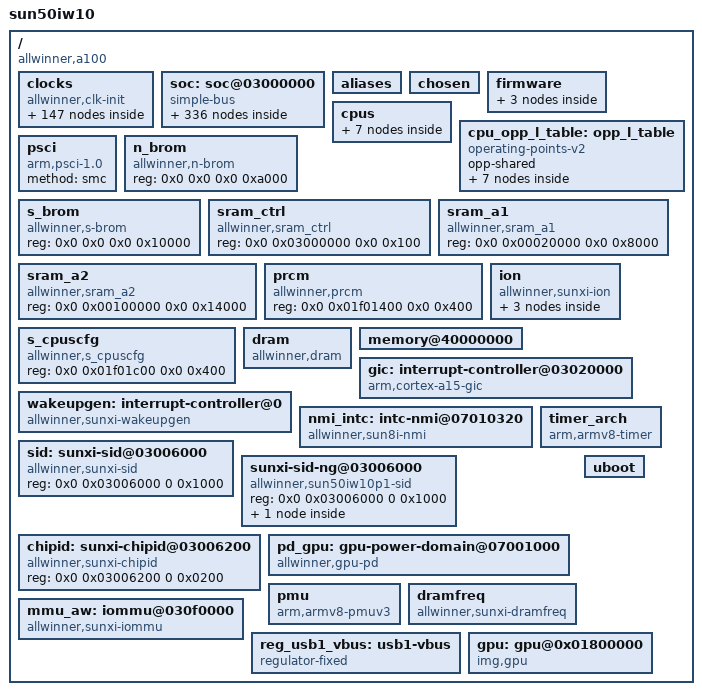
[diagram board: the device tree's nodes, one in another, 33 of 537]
/*
 * Allwinner Technology CO., Ltd. sun50iw10p1 platform
 *
 * modify base on juno.dts
 */
/dts-v1/;

/memreserve/ 0x48000000 0x01000000; /* atf */
/memreserve/ 0x48100000 0x00008000; /* arisc dram code */

#include <dt-bindings/interrupt-controller/arm-gic.h>
#include <dt-bindings/gpio/gpio.h>
/*#include "sun50iw10p1-clk.dtsi"*/
/*#include "sun50iw10p1-pinctrl.dtsi"*/
#include <dt-bindings/thermal/thermal.h>
/ {
	model = "sun50iw10";
	compatible = "allwinner,a100", "arm,sun50iw10p1";
	interrupt-parent = <&wakeupgen>;
	#address-cells = <2>;
	#size-cells = <2>;

	clocks {
		compatible = "allwinner,clk-init";
		device_type = "clocks";
		#address-cells = <2>;
		#size-cells = <2>;
		ranges;
		reg = <0x0 0x03001000 0x0 0x1000>,	/*cpux space*/
		      <0x0 0x07010000 0x0 0x400>,	/*cpus space*/
		      <0x0 0x07000000 0x0 0x4>;

	/* register fixed rate clock*/
			clk_losc: losc {
				#clock-cells = <0>;
				compatible = "allwinner,fixed-clock";
				clock-frequency = <32768>;
				clock-output-names = "losc";
			};
			clk_iosc: iosc {
				#clock-cells = <0>;
				compatible = "allwinner,fixed-clock";
				clock-frequency = <16000000>;
				clock-output-names = "iosc";
			};
			clk_hosc: hosc {
				#clock-cells = <0>;
				compatible = "allwinner,fixed-clock";
				clock-frequency = <24000000>;
				clock-output-names = "hosc";
			};
			clk_osc48m: osc48m {
				#clock-cells = <0>;
				compatible = "allwinner,fixed-clock";
				clock-frequency = <48000000>;
				clock-output-names = "osc48m";
			};
			clk_hoscdiv32k: hoscdiv32k {
				#clock-cells = <0>;
				compatible = "allwinner,fixed-clock";
				clock-frequency = <32768>;
				clock-output-names = "hoscdiv32k";
			};
			clk_pll_periph0div25m:pll_periph0div25m {
				#clock-cells = <0>;
				compatible = "allwinner,fixed-clock";
				clock-frequency = <25000000>;
				clock-output-names = "pll_periph0div25m";
			};

	/* register allwinner,pll-clock */
			clk_pll_cpu: pll_cpu {
				#clock-cells = <0>;
				compatible = "allwinner,pll-clock";
				lock-mode = "new";
				clock-output-names = "pll_cpu";
			};
			clk_pll_ddr: pll_ddr {
				#clock-cells = <0>;
				compatible = "allwinner,pll-clock";
				lock-mode = "new";
				clock-output-names = "pll_ddr";
			};
			clk_pll_periph0: pll_periph0 {
				#clock-cells = <0>;
				compatible = "allwinner,pll-clock";
				assigned-clock-rates = <600000000>;
				lock-mode = "new";
				clock-output-names = "pll_periph0";
			};
			clk_pll_periph1: pll_periph1 {
				#clock-cells = <0>;
				compatible = "allwinner,pll-clock";
				assigned-clock-rates = <600000000>;
				lock-mode = "new";
				clock-output-names = "pll_periph1";
			};
			clk_pll_gpu: pll_gpu {
				#clock-cells = <0>;
				compatible = "allwinner,pll-clock";
				lock-mode = "new";
				clock-output-names = "pll_gpu";
			};
			clk_pll_video0x4: pll_video0x4 {
				#clock-cells = <0>;
				compatible = "allwinner,pll-clock";
				lock-mode = "new";
				clock-output-names = "pll_video0x4";
			};
			clk_pll_video1x4: pll_video1x4 {
				#clock-cells = <0>;
				compatible = "allwinner,pll-clock";
				lock-mode = "new";
				clock-output-names = "pll_video1x4";
			};
			clk_pll_video2: pll_video2 {
				#clock-cells = <0>;
				compatible = "allwinner,pll-clock";
				lock-mode = "new";
				assigned-clocks = <&clk_pll_video2>;
				assigned-clock-rates = <336000000>;
				clock-output-names = "pll_video2";
			};
			clk_pll_video3: pll_video3 {
				#clock-cells = <0>;
				compatible = "allwinner,pll-clock";
				lock-mode = "new";
				assigned-clocks = <&clk_pll_video3>;
				assigned-clock-rates = <300000000>;
				clock-output-names = "pll_video3";
			};
			clk_pll_ve: pll_ve {
				#clock-cells = <0>;
				compatible = "allwinner,pll-clock";
				device_type = "clk_pll_ve";
				lock-mode = "new";
				/*assigned-clock-rates = <??>*/
				clock-output-names = "pll_ve";
			};
			clk_pll_com: pll_com {
				#clock-cells = <0>;
				compatible = "allwinner,pll-clock";
				assigned-clocks = <&clk_pll_com>;
				assigned-clock-rates = <600000000>;
				lock-mode = "new";
				clock-output-names = "pll_com";
			};
			clk_pll_audiox4: pll_audiox4 {
				#clock-cells = <0>;
				compatible = "allwinner,pll-clock";
				assigned-clocks = <&clk_pll_audiox4>;
				assigned-clock-rates = <98304000>;
				lock-mode = "new";
				clock-output-names = "pll_audiox4";
			};

	/* register fixed factor clock*/
			clk_pll_periph0x2: pll_periph0x2 {
				#clock-cells = <0>;
				compatible = "allwinner,fixed-factor-clock";
				clocks = <&clk_pll_periph0>;
				clock-mult = <2>;
				clock-div = <1>;
				clock-output-names = "pll_periph0x2";
			};
			clk_pll_periph0x4: pll_periph0x4 {
				#clock-cells = <0>;
				compatible = "allwinner,fixed-factor-clock";
				clocks = <&clk_pll_periph0>;
				clock-mult = <4>;
				clock-div = <1>;
				clock-output-names = "pll_periph0x4";
			};
			clk_periph32k: periph32k {
				#clock-cells = <0>;
				compatible = "allwinner,fixed-factor-clock";
				clocks = <&clk_pll_periph0>;
				clock-mult = <2>;
				clock-div = <36621>;
				clock-output-names = "periph32k";
			};
			clk_pll_periph1x2: pll_periph1x2 {
				#clock-cells = <0>;
				compatible = "allwinner,fixed-factor-clock";
				clocks = <&clk_pll_periph1>;
				clock-mult = <2>;
				clock-div = <1>;
				clock-output-names = "pll_periph1x2";
			};
			clk_pll_comdiv5: pll_comdiv5 {
				#clock-cells = <0>;
				compatible = "allwinner,fixed-factor-clock";
				clocks = <&clk_pll_com>;
				clock-mult = <1>;
				clock-div = <5>;
				clock-output-names = "pll_comdiv5";
			};
			clk_pll_audiox8: pll_audiox8 {
				#clock-cells = <0>;
				compatible = "allwinner,fixed-factor-clock";
				clocks = <&clk_pll_audiox4>;
				clock-mult = <2>;
				clock-div = <1>;
				clock-output-names = "pll_audiox8";
			};

			clk_pll_audio: pll_audio {
				#clock-cells = <0>;
				compatible = "allwinner,fixed-factor-clock";
				clocks = <&clk_pll_audiox4>;
				clock-mult = <1>;
				clock-div = <4>;
				clock-output-names = "pll_audio";
			};
			clk_pll_audiox2: pll_audiox2 {
				#clock-cells = <0>;
				compatible = "allwinner,fixed-factor-clock";
				clocks = <&clk_pll_audiox4>;
				clock-mult = <1>;
				clock-div = <2>;
				clock-output-names = "pll_audiox2";
			};
			clk_pll_video0: pll_video0 {
				#clock-cells = <0>;
				compatible = "allwinner,fixed-factor-clock";
				clocks = <&clk_pll_video0x4>;
				clock-mult = <1>;
				clock-div = <4>;
				clock-output-names = "pll_video0";
			};
			clk_pll_video0x2: pll_video0x2 {
				#clock-cells = <0>;
				compatible = "allwinner,fixed-factor-clock";
				clocks = <&clk_pll_video0x4>;
				clock-mult = <1>;
				clock-div = <2>;
				clock-output-names = "pll_video0x2";
			};
			clk_pll_video1: pll_video1 {
				#clock-cells = <0>;
				compatible = "allwinner,fixed-factor-clock";
				clocks = <&clk_pll_video1x4>;
				clock-mult = <1>;
				clock-div = <4>;
				clock-output-names = "pll_video1";
			};
			clk_pll_video1x2: pll_video1x2 {
				#clock-cells = <0>;
				compatible = "allwinner,fixed-factor-clock";
				clocks = <&clk_pll_video1x4>;
				clock-mult = <1>;
				clock-div = <2>;
				clock-output-names = "pll_video1x2";
			};
			clk_pll_video2x2: pll_video2x2 {
				#clock-cells = <0>;
				compatible = "allwinner,fixed-factor-clock";
				clocks = <&clk_pll_video2>;
				clock-mult = <2>;
				clock-div = <1>;
				clock-output-names = "pll_video2x2";
			};
			clk_pll_video2x4: pll_video2x4 {
				#clock-cells = <0>;
				compatible = "allwinner,fixed-factor-clock";
				clocks = <&clk_pll_video2>;
				clock-mult = <4>;
				clock-div = <1>;
				clock-output-names = "pll_video2x4";
			};
			clk_pll_video3x2: pll_video3x2 {
				#clock-cells = <0>;
				compatible = "allwinner,fixed-factor-clock";
				clocks = <&clk_pll_video3>;
				clock-mult = <2>;
				clock-div = <1>;
				clock-output-names = "pll_video3x2";
			};
			clk_pll_video3x4: pll_video3x4 {
				#clock-cells = <0>;
				compatible = "allwinner,fixed-factor-clock";
				clocks = <&clk_pll_video3>;
				clock-mult = <4>;
				clock-div = <1>;
				clock-output-names = "pll_video3x4";
			};
			clk_hoscd2: hoscd2 {
				#clock-cells = <0>;
				compatible = "allwinner,fixed-factor-clock";
				clocks = <&clk_hosc>;
				clock-mult = <1>;
				clock-div = <2>;
				clock-output-names = "hoscd2";
			};
			clk_osc48md4: osc48md4 {
				#clock-cells = <0>;
				compatible = "allwinner,fixed-factor-clock";
				clocks = <&clk_osc48m>;
				clock-mult = <1>;
				clock-div = <4>;
				clock-output-names = "osc48md4";
			};
			clk_pll_periph0d6: pll_periph0d6 {
				#clock-cells = <0>;
				compatible = "allwinner,fixed-factor-clock";
				clocks = <&clk_pll_periph0>;
				clock-mult = <1>;
				clock-div = <6>;
				clock-output-names = "pll_periph0d6";
			};

	/* register allwinner,periph-clock */
			clk_cpu: cpu {
				#clock-cells = <0>;
				compatible = "allwinner,cpu-clock";
				clock-output-names = "cpu";
			};
			clk_axi: axi {
				#clock-cells = <0>;
				compatible = "allwinner,periph-clock";
				clock-output-names = "axi";
			};
			clk_cpuapb: cpuapb {
				#clock-cells = <0>;
				compatible = "allwinner,periph-clock";
				clock-output-names = "cpuapb";
			};
			clk_psi: psi {
				#clock-cells = <0>;
				compatible = "allwinner,periph-clock";
				clock-output-names = "psi";
			};
			clk_ahb1: ahb1 {
				#clock-cells = <0>;
				compatible = "allwinner,periph-clock";
				clock-output-names = "ahb1";
			};
			clk_ahb2: ahb2 {
				#clock-cells = <0>;
				compatible = "allwinner,periph-clock";
				clock-output-names = "ahb2";
			};
			clk_ahb3: ahb3 {
				#clock-cells = <0>;
				compatible = "allwinner,periph-clock";
				clock-output-names = "ahb3";
			};
			clk_apb1: apb1 {
				#clock-cells = <0>;
				compatible = "allwinner,periph-clock";
				clock-output-names = "apb1";
			};
			clk_apb2: apb2 {
				#clock-cells = <0>;
				compatible = "allwinner,periph-clock";
				clock-output-names = "apb2";
			};
			clk_mbus: mbus {
				#clock-cells = <0>;
				compatible = "allwinner,periph-clock";
				clock-output-names = "mbus";
			};
			clk_de0: de0 {
				#clock-cells = <0>;
				compatible = "allwinner,periph-clock";
				assigned-clock-parents = <&clk_pll_periph0x2>;
				assigned-clock-rates = <300000000>;
				assigned-clocks = <&clk_de0>;
				clock-output-names = "de0";
			};
			clk_de1: de1 {
				#clock-cells = <0>;
				compatible = "allwinner,periph-clock";
				assigned-clock-parents = <&clk_pll_periph0x2>;
				assigned-clock-rates = <300000000>;
				assigned-clocks = <&clk_de1>;
				clock-output-names = "de1";
			};
			clk_g2d: g2d {
				#clock-cells = <0>;
				compatible = "allwinner,periph-clock";
				clock-output-names = "g2d";
				assigned-clock-parents = <&clk_pll_periph0x2>;
				assigned-clock-rates = <300000000>;
				assigned-clocks = <&clk_g2d>;
			};

			clk_ee: ee {
				#clock-cells = <0>;
				compatible = "allwinner,periph-clock";
				assigned-clock-parents = <&clk_pll_periph0x2>;
				assigned-clock-rates = <300000000>;
				assigned-clocks = <&clk_ee>;
				clock-output-names = "ee";
			};
			clk_panel: panel {
				#clock-cells = <0>;
				compatible = "allwinner,periph-clock";
				assigned-clock-parents = <&clk_pll_video2>;
				assigned-clock-rates = <30000000>;
				assigned-clocks = <&clk_panel>;
				clock-output-names = "panel";
			};

			clk_gpu: gpu {
				#clock-cells = <0>;
				compatible = "allwinner,periph-clock";
				clock-output-names = "gpu";
			};
			clk_ce: ce {
				#clock-cells = <0>;
				compatible = "allwinner,periph-clock";
				clock-output-names = "ce";
			};
			clk_ve: ve {
				#clock-cells = <0>;
				compatible = "allwinner,periph-clock";
				clock-output-names = "ve";
			};
			clk_dma: dma {
				#clock-cells = <0>;
				compatible = "allwinner,periph-clock";
				clock-output-names = "dma";
			};
			clk_msgbox: msgbox {
				#clock-cells = <0>;
				compatible = "allwinner,periph-clock";
				clock-output-names = "msgbox";
			};
			clk_hwspinlock_rst: hwspinlock_rst {
				#clock-cells = <0>;
				compatible = "allwinner,periph-clock";
				clock-output-names = "hwspinlock_rst";
			};
			clk_hwspinlock_bus: hwspinlock_bus {
				#clock-cells = <0>;
				compatible = "allwinner,periph-clock";
				clock-output-names = "hwspinlock_bus";
			};
			clk_hstimer: hstimer {
				#clock-cells = <0>;
				compatible = "allwinner,periph-clock";
				clock-output-names = "hstimer";
			};
			clk_avs: avs {
				#clock-cells = <0>;
				compatible = "allwinner,periph-clock";
				clock-output-names = "avs";
			};
			clk_dbgsys: dbgsys {
				#clock-cells = <0>;
				compatible = "allwinner,periph-clock";
				clock-output-names = "dbgsys";
			};
			clk_pwm: pwm {
				#clock-cells = <0>;
				compatible = "allwinner,periph-clock";
				clock-output-names = "pwm";
			};
			clk_iommu: iommu {
				#clock-cells = <0>;
				compatible = "allwinner,periph-clock";
				clock-output-names = "iommu";
			};
			clk_sdram: sdram {
				#clock-cells = <0>;
				compatible = "allwinner,periph-clock";
				clock-output-names = "sdram";
			};
			clk_nand0: nand0 {
				#clock-cells = <0>;
				compatible = "allwinner,periph-clock";
				clock-output-names = "nand0";
			};
			clk_nand1: nand1 {
				#clock-cells = <0>;
				compatible = "allwinner,periph-clock";
				clock-output-names = "nand1";
			};
			clk_sdmmc0_mod: sdmmc0_mod {
				#clock-cells = <0>;
				compatible = "allwinner,periph-clock";
				clock-output-names = "sdmmc0_mod";
			};
			clk_sdmmc0_bus: sdmmc0_bus {
				#clock-cells = <0>;
				compatible = "allwinner,periph-clock";
				clock-output-names = "sdmmc0_bus";
			};
			clk_sdmmc0_rst: sdmmc0_rst {
				#clock-cells = <0>;
				compatible = "allwinner,periph-clock";
				clock-output-names = "sdmmc0_rst";
			};
			clk_sdmmc1_mod: sdmmc1_mod {
				#clock-cells = <0>;
				compatible = "allwinner,periph-clock";
				clock-output-names = "sdmmc1_mod";
			};
			clk_sdmmc1_bus: sdmmc1_bus {
				#clock-cells = <0>;
				compatible = "allwinner,periph-clock";
				clock-output-names = "sdmmc1_bus";
			};
			clk_sdmmc1_rst: sdmmc1_rst {
				#clock-cells = <0>;
				compatible = "allwinner,periph-clock";
				clock-output-names = "sdmmc1_rst";
			};
			clk_sdmmc2_mod: sdmmc2_mod {
				#clock-cells = <0>;
				compatible = "allwinner,periph-clock";
				clock-output-names = "sdmmc2_mod";
			};
			clk_sdmmc2_bus: sdmmc2_bus {
				#clock-cells = <0>;
				compatible = "allwinner,periph-clock";
				clock-output-names = "sdmmc2_bus";
			};
			clk_sdmmc2_rst: sdmmc2_rst {
				#clock-cells = <0>;
				compatible = "allwinner,periph-clock";
				clock-output-names = "sdmmc2_rst";
			};
			clk_uart0: uart0 {
				#clock-cells = <0>;
				compatible = "allwinner,periph-clock";
				clock-output-names = "uart0";
			};
			clk_uart1: uart1 {
				#clock-cells = <0>;
				compatible = "allwinner,periph-clock";
				clock-output-names = "uart1";
			};
			clk_uart2: uart2 {
				#clock-cells = <0>;
				compatible = "allwinner,periph-clock";
				clock-output-names = "uart2";
			};
			clk_uart3: uart3 {
				#clock-cells = <0>;
				compatible = "allwinner,periph-clock";
				clock-output-names = "uart3";
			};
			clk_uart4: uart4 {
				#clock-cells = <0>;
				compatible = "allwinner,periph-clock";
				clock-output-names = "uart4";
			};
			clk_uart5: uart5 {
				#clock-cells = <0>;
				compatible = "allwinner,periph-clock";
				clock-output-names = "uart5";
			};
			clk_uart6: uart6 {
				#clock-cells = <0>;
				compatible = "allwinner,periph-clock";
				clock-output-names = "uart6";
			};
			clk_twi0: twi0 {
				#clock-cells = <0>;
				compatible = "allwinner,periph-clock";
				clock-output-names = "twi0";
			};
			clk_twi1: twi1 {
				#clock-cells = <0>;
				compatible = "allwinner,periph-clock";
				clock-output-names = "twi1";
			};
			clk_stwi0: stwi0 {
				#clock-cells = <0>;
				compatible = "allwinner,periph-cpus-clock";
				clock-output-names = "stwi0";
			};
			clk_stwi1: stwi1 {
				#clock-cells = <0>;
				compatible = "allwinner,periph-cpus-clock";
				clock-output-names = "stwi1";
			};
			clk_twi2: twi2 {
				#clock-cells = <0>;
				compatible = "allwinner,periph-clock";
				clock-output-names = "twi2";
			};
			clk_twi3: twi3 {
				#clock-cells = <0>;
				compatible = "allwinner,periph-clock";
				clock-output-names = "twi3";
			};
			clk_twi4: twi4 {
				#clock-cells = <0>;
				compatible = "allwinner,periph-clock";
				clock-output-names = "twi4";
			};
			clk_twi5: twi5 {
				#clock-cells = <0>;
				compatible = "allwinner,periph-clock";
				clock-output-names = "twi5";
			};
			clk_scr0: scr0 {
				#clock-cells = <0>;
				compatible = "allwinner,periph-clock";
				clock-output-names = "scr0";
			};
			clk_spi0: spi0 {
				#clock-cells = <0>;
				compatible = "allwinner,periph-clock";
				clock-output-names = "spi0";
			};
			clk_spi1: spi1 {
				#clock-cells = <0>;
				compatible = "allwinner,periph-clock";
				clock-output-names = "spi1";
			};
			clk_spi2: spi2 {
				#clock-cells = <0>;
				compatible = "allwinner,periph-clock";
				clock-output-names = "spi2";
			};
			clk_gmac0_25m: gmac0_25m {
				#clock-cells = <0>;
				compatible = "allwinner,periph-clock";
				clock-output-names = "gmac0_25m";
			};
			clk_gmac1_25m: gmac1_25m {
				#clock-cells = <0>;
				compatible = "allwinner,periph-clock";
				clock-output-names = "gmac1_25m";
			};
			clk_gmac0: gmac0 {
				#clock-cells = <0>;
				compatible = "allwinner,periph-clock";
				clock-output-names = "gmac0";
			};
			clk_gmac1: gmac1 {
				#clock-cells = <0>;
				compatible = "allwinner,periph-clock";
				clock-output-names = "gmac1";
			};
			clk_gpadc: gpadc {
				#clock-cells = <0>;
				compatible = "allwinner,periph-clock";
				clock-output-names = "gpadc";
			};
			clk_irtx: irtx {
				#clock-cells = <0>;
				compatible = "allwinner,periph-clock";
				clock-output-names = "irtx";
			};
			clk_ths: ths {
				#clock-cells = <0>;
				compatible = "allwinner,periph-clock";
				clock-output-names = "ths";
			};
			clk_i2s0: i2s0 {
				#clock-cells = <0>;
				compatible = "allwinner,periph-clock";
				clock-output-names = "i2s0";
			};
			clk_i2s1: i2s1 {
				#clock-cells = <0>;
				compatible = "allwinner,periph-clock";
				clock-output-names = "i2s1";
			};
			clk_i2s2: i2s2 {
				#clock-cells = <0>;
				compatible = "allwinner,periph-clock";
				clock-output-names = "i2s2";
			};
			clk_i2s3: i2s3 {
				#clock-cells = <0>;
				compatible = "allwinner,periph-clock";
				clock-output-names = "i2s3";
			};
			clk_spdif: spdif {
				#clock-cells = <0>;
				compatible = "allwinner,periph-clock";
				clock-output-names = "spdif";
			};
			clk_dmic: dmic {
				#clock-cells = <0>;
				compatible = "allwinner,periph-clock";
				clock-output-names = "dmic";
			};
			clk_codec_dac_1x: codec_dac_1x {
				#clock-cells = <0>;
				compatible = "allwinner,periph-clock";
				clock-output-names = "codec_dac_1x";
			};
			clk_codec_adc_1x: codec_adc_1x {
				#clock-cells = <0>;
				compatible = "allwinner,periph-clock";
				clock-output-names = "codec_adc_1x";
			};
			clk_codec_4x: codec_4x {
				#clock-cells = <0>;
				compatible = "allwinner,periph-clock";
				clock-output-names = "codec_4x";
			};
			clk_usbphy0: usbphy0 {
				#clock-cells = <0>;
				compatible = "allwinner,periph-clock";
				clock-output-names = "usbphy0";
			};
			clk_usbphy1: usbphy1 {
				#clock-cells = <0>;
				compatible = "allwinner,periph-clock";
				clock-output-names = "usbphy1";
			};
			clk_usbohci0: usbohci0 {
				#clock-cells = <0>;
				compatible = "allwinner,periph-clock";
				clock-output-names = "usbohci0";
			};
			clk_usbohci0_12m: usbohci0_12m {
				#clock-cells = <0>;
				compatible = "allwinner,periph-clock";
				clock-output-names = "usbohci0_12m";
			};
			clk_usbohci1: usbohci1 {
				#clock-cells = <0>;
				compatible = "allwinner,periph-clock";
				clock-output-names = "usbohci1";
			};
			clk_usbohci1_12m: usbohci1_12m {
				#clock-cells = <0>;
				compatible = "allwinner,periph-clock";
				clock-output-names = "usbohci1_12m";
			};
			clk_usbehci0: usbehci0 {
				#clock-cells = <0>;
				compatible = "allwinner,periph-clock";
				clock-output-names = "usbehci0";
			};
			clk_usbehci1: usbehci1 {
				#clock-cells = <0>;
				compatible = "allwinner,periph-clock";
				clock-output-names = "usbehci1";
			};
			clk_usbotg: usbotg {
				#clock-cells = <0>;
				compatible = "allwinner,periph-clock";
				clock-output-names = "usbotg";
			};
			clk_display_top: display_top {
				#clock-cells = <0>;
				compatible = "allwinner,periph-clock";
				clock-output-names = "display_top";
			};
			clk_dpss_top0: dpss_top0 {
				#clock-cells = <0>;
				compatible = "allwinner,periph-clock";
				clock-output-names = "dpss_top0";
			};
			clk_dpss_top1: dpss_top1 {
				#clock-cells = <0>;
				compatible = "allwinner,periph-clock";
				clock-output-names = "dpss_top1";
			};
			clk_tcon_lcd0: tcon_lcd0 {
				#clock-cells = <0>;
				compatible = "allwinner,periph-clock";
				clock-output-names = "tcon_lcd0";
				assigned-clocks = <&clk_tcon_lcd0>;
				assigned-clock-parents = <&clk_pll_video0x4>;
			};
			clk_tcon_lcd1: tcon_lcd1 {
				#clock-cells = <0>;
				compatible = "allwinner,periph-clock";
				clock-output-names = "tcon_lcd1";
				assigned-clocks = <&clk_tcon_lcd1>;
				assigned-clock-parents = <&clk_pll_video1x4>;
			};
			clk_lvds: lvds {
				#clock-cells = <0>;
				compatible = "allwinner,periph-clock";
				clock-output-names = "lvds";
			};
			clk_lvds1: lvds1 {
				#clock-cells = <0>;
				compatible = "allwinner,periph-clock";
				clock-output-names = "lvds1";
			};
			clk_mipi_host: mipi_host {
				#clock-cells = <0>;
				compatible = "allwinner,periph-clock";
				clock-output-names = "mipi_host";
				assigned-clocks = <&clk_mipi_host>;
				assigned-clock-parents = <&clk_pll_periph0>;
				assigned-clock-rates = <150000000>;
			};
			clk_csi_top: csi_top {
				#clock-cells = <0>;
				compatible = "allwinner,periph-clock";
				clock-output-names = "csi_top";
			};
			clk_csi_isp: csi_isp {
				#clock-cells = <0>;
				compatible = "allwinner,periph-clock";
				clock-output-names = "csi_isp";
			};
			clk_csi_master0: csi_master0 {
				#clock-cells = <0>;
				compatible = "allwinner,periph-clock";
				clock-output-names = "csi_master0";
			};
			clk_csi_master1: csi_master1 {
				#clock-cells = <0>;
				compatible = "allwinner,periph-clock";
				clock-output-names = "csi_master1";
			};
			clk_pio: pio {
				#clock-cells = <0>;
				compatible = "allwinner,periph-clock";
				clock-output-names = "pio";
			};
			clk_ledc: ledc {
				#clock-cells = <0>;
				compatible = "allwinner,periph-clock";
				clock-output-names = "ledc";
			};

	/*cpus space clocks from PRCM-SPEC*/
			clk_cpurcir: cpurcir {
				#clock-cells = <0>;
				compatible = "allwinner,periph-cpus-clock";
				clock-output-names = "cpurcir";
			};
			clk_losc_out: losc_out {
				#clock-cells = <0>;
				compatible = "allwinner,periph-cpus-clock";
				clock-output-names = "losc_out";
			};
			/* clk below are read only , just to keep a clock tree */
			clk_cpurcpus_pll: cpurcpus_pll {
				#clock-cells = <0>;
				compatible = "allwinner,periph-cpus-clock";
				clock-output-names = "cpurcpus_pll";
			};
			clk_cpurcpus: cpurcpus {
				#clock-cells = <0>;
				compatible = "allwinner,periph-cpus-clock";
				clock-output-names = "cpurcpus";
			};
			clk_cpurahbs: cpurahbs {
				#clock-cells = <0>;
				compatible = "allwinner,periph-cpus-clock";
				clock-output-names = "cpurahbs";
			};
			clk_cpurapbs1: cpurapbs1 {
				#clock-cells = <0>;
				compatible = "allwinner,periph-cpus-clock";
				clock-output-names = "cpurapbs1";
			};
			clk_cpurapbs2_pll: cpurapbs2_pll {
				#clock-cells = <0>;
				compatible = "allwinner,periph-cpus-clock";
				clock-output-names = "cpurapbs2_pll";
			};
			clk_cpurapbs2: cpurapbs2 {
				#clock-cells = <0>;
				compatible = "allwinner,periph-cpus-clock";
				clock-output-names = "cpurapbs2";
			};
			clk_ppu: ppu {
				#clock-cells = <0>;
				compatible = "allwinner,periph-cpus-clock";
				clock-output-names = "ppu";
			};
			clk_cpurpio: cpurpio {
				#clock-cells = <0>;
				compatible = "allwinner,periph-cpus-clock";
				clock-output-names = "cpurpio";
			};
			clk_dcxo_out: dcxo_out {
				#clock-cells = <0>;
				compatible = "allwinner,periph-cpus-clock";
				clock-output-names = "dcxo_out";
			};
			clk_suart: suart {
				#clock-cells = <0>;
				compatible = "allwinner,periph-cpus-clock";
				clock-output-names = "suart";
			};
			clk_lradc: lradc {
				#clock-cells = <0>;
				compatible = "allwinner,periph-clock";
				clock-output-names = "lradc";
			};
		};

	soc: soc@03000000 {
		compatible = "simple-bus";
		#address-cells = <2>;
		#size-cells = <2>;
		ranges;
		device_type = "soc";

		r_pio: pinctrl@07022000 {
			compatible = "allwinner,sun50iw10p1-r-pinctrl";
			reg = <0x0 0x07022000 0x0 0x400>;
			interrupts = <GIC_SPI 111 IRQ_TYPE_LEVEL_HIGH>;
			clocks = <&clk_cpurpio>, <&clk_losc>, <&clk_hosc>;
			device_type = "r_pio";
			//resets = <&apb0_rst 0>;
			gpio-controller;
			interrupt-controller;
			#interrupt-cells = <3>;
			#size-cells = <0>;
			#gpio-cells = <6>;
			input-debounce = <0>;

			s_rsb0_pins_a: s_rsb0@0 {
				allwinner,pins = "PL0", "PL1";
				allwinner,function = "s_rsb0";
				allwinner,muxsel = <2>;
				allwinner,drive = <2>;
				allwinner,pull = <1>;
			};

			s_uart0_pins_a: s_uart0@0 {
				allwinner,pins = "PL2", "PL3";
				allwinner,function = "s_uart0";
				allwinner,muxsel = <2>;
				allwinner,drive = <1>;
				allwinner,pull = <1>;
			};

			s_uart0_pins_b: s_uart0@1 {
				allwinner,pins = "PL2", "PL3";
				allwinner,function = "io_disabled";  /* io_disabled */
				allwinner,muxsel = <7>;
				allwinner,drive = <1>;
				allwinner,pull = <1>;
			};

			s_twi0_pins_a: s_twi0@0 {
				allwinner,pins = "PL0", "PL1";
				allwinner,pname = "s_twi0_scl", "s_twi0_sda";
				allwinner,function = "s_twi0";
				allwinner,muxsel = <2>;
				allwinner,drive = <1>;
				allwinner,pull = <1>;
			};

			s_twi0_pins_b: s_twi0@1 {
				allwinner,pins = "PL0", "PL1";
				allwinner,function = "io_disabled";
				allwinner,muxsel = <7>;
				allwinner,drive = <1>;
				allwinner,pull = <0>;
			};

			s_twi1_pins_a: s_twi1@0 {
				allwinner,pins = "PL8", "PL9";
				allwinner,pname = "s_twi1_scl", "s_twi1_sda";
				allwinner,function = "s_twi1";
				allwinner,muxsel = <2>;
				allwinner,drive = <1>;
				allwinner,pull = <1>;
			};

			s_twi1_pins_b: s_twi1@1 {
				allwinner,pins = "PL8", "PL9";
				allwinner,function = "io_disabled";
				allwinner,muxsel = <7>;
				allwinner,drive = <1>;
				allwinner,pull = <0>;
			};

			s_cir0_pins_a: s_cir0@0{
				allwinner,pins = "PL11";
				allwinner,function = "s_cir0";
				allwinner,muxsel = <3>;
				allwinner,drive = <1>;
				allwinner,pull = <1>;
			};
		};

		pio: pinctrl@0300b000 {
			compatible = "allwinner,sun50iw10p1-pinctrl";
			reg = <0x0 0x0300b000 0x0 0x400>;
			interrupts = <GIC_SPI 54 IRQ_TYPE_LEVEL_HIGH>,  /* AW1855_GIC_Spec: GPIOB: 86-32=54 */
				   <GIC_SPI 55 IRQ_TYPE_LEVEL_HIGH>,
				   <GIC_SPI 56 IRQ_TYPE_LEVEL_HIGH>,
				   <GIC_SPI 57 IRQ_TYPE_LEVEL_HIGH>,
				   <GIC_SPI 58 IRQ_TYPE_LEVEL_HIGH>,
				   <GIC_SPI 59 IRQ_TYPE_LEVEL_HIGH>,
				   <GIC_SPI 60 IRQ_TYPE_LEVEL_HIGH>,
				   <GIC_SPI 61 IRQ_TYPE_LEVEL_HIGH>,
				   <GIC_SPI 62 IRQ_TYPE_LEVEL_HIGH>;
			device_type = "pio";
			clocks = <&clk_pio>, <&clk_losc>, <&clk_hosc>;
			gpio-controller;
			interrupt-controller;
			#interrupt-cells = <3>;
			#size-cells = <0>;
			#gpio-cells = <6>;
			/* takes the debounce time in usec as argument */
			input-debounce = <0 0 0 0 0 0 0 0 0>;

			vdevice_pins_a: vdevice@0 {
				allwinner,pins = "PB0", "PB1";
				allwinner,function = "Vdevice";
				allwinner,muxsel = <5>;
				allwinner,drive = <1>;
				allwinner,pull = <1>;
			};
			/* FPGA stage: PB8 PB9, IC stage: PB9 PB10*/
			uart0_pins_a: uart0@0 {
				allwinner,pins = "PB9", "PB10";
				allwinner,pname = "uart0_tx", "uart0_rx";
				allwinner,function = "uart0";
				allwinner,muxsel = <2>;
				allwinner,drive = <1>;
				allwinner,pull = <1>;
			};

			uart0_pins_b: uart0@1 {
				allwinner,pins = "PB9", "PB10";
				allwinner,function = "uart0";  /* io_disabled */
				allwinner,muxsel = <7>;
				allwinner,drive = <1>;
				allwinner,pull = <0>;
			};

			uart1_pins_a: uart1@0 {
				allwinner,pins = "PG6", "PG7", "PG8", "PG9";
				allwinner,pname = "uart1_tx", "uart1_rx",
						  "uart1_rts", "uart1_cts";
				allwinner,function = "uart1";
				allwinner,muxsel = <2>;
				allwinner,drive = <1>;
				allwinner,pull = <1>;
			};

			uart1_pins_b: uart1@1 {
				allwinner,pins = "PG6", "PG7", "PG8", "PG9";
				allwinner,function = "io_disabled";
				allwinner,muxsel = <7>;
				allwinner,drive = <1>;
				allwinner,pull = <0>;
			};

			uart2_pins_a: uart2@0 {
				allwinner,pins = "PB0", "PB1", "PB2", "PB3";
				allwinner,pname = "uart2_tx", "uart2_rx",
						  "uart2_rts", "uart2_cts";
				allwinner,function = "uart2";
				allwinner,muxsel = <2>;
				allwinner,drive = <1>;
				allwinner,pull = <1>;
			};

			uart2_pins_b: uart2@1 {
				allwinner,pins = "PB0", "PB1", "PB2", "PB3";
				allwinner,function = "io_disabled";
				allwinner,muxsel = <7>;
				allwinner,drive = <1>;
				allwinner,pull = <0>;
			};

			uart3_pins_a: uart3@0 {
				allwinner,pins = "PH4", "PH5", "PH6", "PH7";
				allwinner,pname = "uart3_tx", "uart3_rx",
						  "uart3_rts", "uart3_cts";
				allwinner,function = "uart3";
				allwinner,muxsel = <2>;
				allwinner,drive = <1>;
				allwinner,pull = <1>;
			};

			uart3_pins_b: uart3@1 {
				allwinner,pins = "PH4", "PH5", "PH6", "PH7";
				allwinner,function = "io_disabled";
				allwinner,muxsel = <7>;
				allwinner,drive = <1>;
				allwinner,pull = <0>;
			};

			uart4_pins_a: uart4@0 {
				allwinner,pins = "PD18", "PD19", "PD20", "PD21";
				allwinner,pname = "uart4_tx", "uart4_rx",
						  "uart4_rts", "uart4_cts";
				allwinner,function = "uart4";
				allwinner,muxsel = <4>;
				allwinner,drive = <1>;
				allwinner,pull = <1>;
			};

			uart4_pins_b: uart4@1 {
				allwinner,pins = "PD18", "PD19", "PD20", "PD21";
				allwinner,function = "io_disabled";
				allwinner,muxsel = <7>;
				allwinner,drive = <1>;
				allwinner,pull = <0>;
			};

			uart5_pins_a: uart5@0 {
				allwinner,pins = "PI2", "PI3", "PI4", "PI5";
				allwinner,pname = "uart5_tx", "uart5_rx",
						  "uart5_rts", "uart5_cts";
				allwinner,function = "uart5";
				allwinner,muxsel = <2>;
				allwinner,drive = <1>;
				allwinner,pull = <1>;
			};

			uart5_pins_b: uart5@1 {
				allwinner,pins = "PI2", "PI3", "PI4", "PI5";
				allwinner,function = "io_disabled";
				allwinner,muxsel = <7>;
				allwinner,drive = <1>;
				allwinner,pull = <0>;
			};

			uart6_pins_a: uart6@0 {
				allwinner,pins = "PI6", "PI7", "PI13", "PI14";
				allwinner,pname = "uart6_tx", "uart6_rx",
						  "uart6_rts", "uart6_cts";
				allwinner,function = "uart6";
				allwinner,muxsel = <2>;
				allwinner,drive = <1>;
				allwinner,pull = <1>;
			};

			uart6_pins_b: uart6@1 {
				allwinner,pins = "PI6", "PI7", "PI13", "PI14";
				allwinner,function = "io_disabled";
				allwinner,muxsel = <7>;
				allwinner,drive = <1>;
				allwinner,pull = <0>;
			};

			ir0_pins_a: ir0@0 {
				allwinner,pins = "PH3";
				allwinner,pname = "it-tx";
				allwinner,function = "ir0";
				allwinner,muxsel = <3>;
				allwinner,drive = <1>;
				allwinner,pull = <0>;
			};

			ir0_pins_b: ir0@1 {
				allwinner,pins = "PH3";
				allwinner,pname = "io_disabled";
				allwinner,function = "io_disabled";
				allwinner,muxsel = <7>;
				allwinner,drive = <1>;
				allwinner,pull = <0>;
			};

			twi0_pins_a: twi0@0 {
				allwinner,pins = "PH0", "PH1";
				allwinner,pname = "twi0_scl", "twi0_sda";
				allwinner,function = "twi0";
				allwinner,muxsel = <2>;
				allwinner,drive = <1>;
				allwinner,pull = <0>;
			};

			twi0_pins_b: twi0@1 {
				allwinner,pins = "PH0", "PH1";
				allwinner,function = "io_disabled";
				allwinner,muxsel = <7>;
				allwinner,drive = <1>;
				allwinner,pull = <0>;
			};

			twi1_pins_a: twi1@0 {
				allwinner,pins = "PH2", "PH3";
				allwinner,pname = "twi1_scl", "twi1_sda";
				allwinner,function = "twi1";
				allwinner,muxsel = <2>;
				allwinner,drive = <1>;
				allwinner,pull = <0>;
			};

			twi1_pins_b: twi1@1 {
				allwinner,pins = "PH2", "PH3";
				allwinner,function = "io_disabled";
				allwinner,muxsel = <7>;
				allwinner,drive = <1>;
				allwinner,pull = <0>;
			};

			twi2_pins_a: twi2@0 {
				allwinner,pins = "PE1", "PE2";
				allwinner,pname = "twi2_scl", "twi2_sda";
				allwinner,function = "twi2";
				allwinner,muxsel = <2>;
				allwinner,drive = <1>;
				allwinner,pull = <0>;
			};

			twi2_pins_b: twi2@1 {
				allwinner,pins = "PE1", "PE2";
				allwinner,function = "io_disabled";
				allwinner,muxsel = <7>;
				allwinner,drive = <1>;
				allwinner,pull = <0>;
			};

			twi3_pins_a: twi3@0 {
				allwinner,pins = "PE3", "PE4";
				allwinner,pname = "twi3_scl", "twi3_sda";
				allwinner,function = "twi3";
				allwinner,muxsel = <2>;
				allwinner,drive = <1>;
				allwinner,pull = <1>;
			};

			twi3_pins_b: twi3@1 {
				allwinner,pins = "PE3", "PE4";
				allwinner,function = "io_disabled";
				allwinner,muxsel = <7>;
				allwinner,drive = <1>;
				allwinner,pull = <0>;
			};

			twi4_pins_a: twi4@0 {
				allwinner,pins = "PI0", "PI1";
				allwinner,pname = "twi4_scl", "twi4_sda";
				allwinner,function = "twi4";
				allwinner,muxsel = <2>;
				allwinner,drive = <1>;
				allwinner,pull = <0>;
			};

			twi4_pins_b: twi4@1 {
				allwinner,pins = "PI0", "PI1";
				allwinner,function = "io_disabled";
				allwinner,muxsel = <7>;
				allwinner,drive = <1>;
				allwinner,pull = <0>;
			};

			twi5_pins_a: twi5@0 {
				allwinner,pins = "PI8", "PI9";
				allwinner,pname = "twi5_scl", "twi5_sda";
				allwinner,function = "twi5";
				allwinner,muxsel = <2>;
				allwinner,drive = <1>;
				allwinner,pull = <0>;
			};

			twi5_pins_b: twi5@1 {
				allwinner,pins = "PI8", "PI9";
				allwinner,function = "io_disabled";
				allwinner,muxsel = <7>;
				allwinner,drive = <1>;
				allwinner,pull = <0>;
			};

			ts0_pins_a: ts0@0 {
				allwinner,pins = "PD0", "PD1", "PD2", "PD3",
						 "PD4", "PD5", "PD6", "PD7",
						 "PD8", "PD9", "PD10", "PD11";
				allwinner,pname = "ts0_clk", "ts0_err",
						  "ts0_sync", "ts0_dvld",
						  "ts0_d0", "ts0_d1",
						  "ts0_d2", "ts0_d3",
						  "ts0_d4", "ts0_d5",
						  "ts0_d6", "ts0_d7";
				allwinner,function = "ts0";
				allwinner,muxsel = <4>;
				allwinner,drive = <1>;
				allwinner,pull = <0>;
			};

			ts0_pins_b: ts0_sleep@0 {
				allwinner,pins = "PD0", "PD1", "PD2", "PD3",
						 "PD4", "PD5", "PD6", "PD7",
						 "PD8", "PD9", "PD10", "PD11";
				allwinner,pname = "ts0_clk", "ts0_err",
						  "ts0_sync", "ts0_dvld",
						  "ts0_d0", "ts0_d1",
						  "ts0_d2", "ts0_d3",
						  "ts0_d4", "ts0_d5",
						  "ts0_d6", "ts0_d7";
				allwinner,function = "io_disabled";
				allwinner,muxsel = <7>;
				allwinner,drive = <1>;
				allwinner,pull = <0>;
			};

			spi0_pins_a: spi0@0 {
				allwinner,pins = "PC2", "PC4", "PC12", "PC15", "PC16";
				allwinner,pname = "spi0_mosi", "spi0_miso",
						  "spi0_sclk", "spi0_wp", "spi0_hold";
				allwinner,function = "spi0";
				allwinner,muxsel = <4>;
				allwinner,drive = <1>;
				allwinner,pull = <0>;
			};

			spi0_pins_b: spi0@1 {
				allwinner,pins = "PC3", "PC7";
				allwinner,pname = "spi0_cs0", "spi0_cs1";
				allwinner,function = "spi0";
				allwinner,muxsel = <4>;
				allwinner,drive = <1>;
				allwinner,pull = <1>;	/* only CS should be pulled up */
			};

			spi0_pins_c: spi0@2 {
				allwinner,pins = "PC2", "PC3", "PC4", "PC7", "PC12", "PC15", "PC16";
				allwinner,function = "io_disabled";
				allwinner,muxsel = <7>;
				allwinner,drive = <1>;
				allwinner,pull = <0>;
			};

			spi1_pins_a: spi1@0 {
				allwinner,pins = "PD11", "PD12", "PD13";
				allwinner,pname = "spi1_sclk", "spi1_mosi",
						  "spi1_miso";
				allwinner,function = "spi1";
				allwinner,muxsel = <4>;
				allwinner,drive = <1>;
				allwinner,pull = <0>;
			};

			spi1_pins_b: spi1@1 {
				allwinner,pins = "PD10";
				allwinner,pname = "spi1_cs0";
				allwinner,function = "spi1";
				allwinner,muxsel = <4>;
				allwinner,drive = <1>;
				allwinner,pull = <1>;	/* only CS should be pulled up */
			};

			spi1_pins_c: spi1@2 {
				allwinner,pins = "PD10", "PD11", "PD12", "PD13";
				allwinner,function = "io_disabled";
				allwinner,muxsel = <7>;
				allwinner,drive = <1>;
				allwinner,pull = <0>;
			};

			spi2_pins_a: spi2@0 {
				allwinner,pins = "PB1", "PB2", "PB3";
				allwinner,pname = "spi2_sclk", "spi2_mosi",
						  "spi2_miso";
				allwinner,function = "spi2";
				allwinner,muxsel = <3>;
				allwinner,drive = <1>;
				allwinner,pull = <0>;
			};

			spi2_pins_b: spi2@1 {
				allwinner,pins = "PB0";
				allwinner,pname = "spi2_cs0";
				allwinner,function = "spi2";
				allwinner,muxsel = <3>;
				allwinner,drive = <1>;
				allwinner,pull = <1>;	/* only CS should be pulled up */
			};

			spi2_pins_c: spi2@2 {
				allwinner,pins = "PB0", "PB1", "PB2", "PB3";
				allwinner,function = "io_disabled";
				allwinner,muxsel = <7>;
				allwinner,drive = <1>;
				allwinner,pull = <0>;
			};

			sdc0_pins_a: sdc0@0 {
				allwinner,pins = "PF0", "PF1", "PF2",
						 "PF3", "PF4", "PF5";
				allwinner,function = "sdc0";
				allwinner,muxsel = <2>;
				allwinner,drive = <3>;
				allwinner,pull = <1>;
			};

			sdc0_pins_b: sdc0@1 {
				allwinner,pins = "PF0", "PF1", "PF2",
						 "PF3", "PF4", "PF5";
				allwinner,function = "io_disabled";
				allwinner,muxsel = <7>;
				allwinner,drive = <1>;
				allwinner,pull = <1>;
			};

			sdc0_pins_c: sdc0@2 {
				allwinner,pins = "PF0", "PF1", "PF2",
						 "PF3", "PF4", "PF5";
				allwinner,function = "uart0_jtag";
				allwinner,muxsel = <3>;
				allwinner,drive = <1>;
				allwinner,pull = <1>;
			};

			sdc1_pins_a: sdc1@0 {
				allwinner,pins = "PG0", "PG1", "PG2",
						 "PG3", "PG4", "PG5";
				allwinner,function = "sdc1";
				allwinner,muxsel = <2>;
				allwinner,drive = <3>;
				allwinner,pull = <1>;
			};

			sdc1_pins_b: sdc1@1 {
				allwinner,pins = "PG0", "PG1", "PG2",
						 "PG3", "PG4", "PG5";
				allwinner,function = "io_disabled";
				allwinner,muxsel = <7>;
				allwinner,drive = <1>;
				allwinner,pull = <1>;
			};

			sdc2_pins_a: sdc2@0 {
				allwinner,pins = "PC1", "PC5", "PC6",
						 "PC8", "PC9", "PC10", "PC11",
						 "PC13", "PC14", "PC15", "PC16";
				allwinner,function = "sdc2";
				allwinner,muxsel = <3>;
				allwinner,drive = <3>;
				allwinner,pull = <1>;
			};

			sdc2_pins_b: sdc2@1 {
				allwinner,pins = "PC0", "PC1", "PC5", "PC6",
						 "PC8", "PC9", "PC10", "PC11",
						 "PC13", "PC14", "PC15", "PC16";
				allwinner,function = "io_disabled";
				allwinner,muxsel = <7>;
				allwinner,drive = <1>;
				allwinner,pull = <1>;
			};

			sdc2_pins_c: sdc2@2 {
				allwinner,pins = "PC0";
				allwinner,function = "sdc2";
				allwinner,muxsel = <3>;
				allwinner,drive = <3>;
				allwinner,pull = <2>;
			};

			sdc3_pins_a: sdc3@0 {
				allwinner,pins = "PI14", "PI13", "PI12",
						 "PI11", "PI10", "PI9";
				allwinner,function = "sdc3";
				allwinner,muxsel = <3>;
				allwinner,drive = <2>;
				allwinner,pull = <1>;
			};

			sdc3_pins_b: sdc3@1 {
				allwinner,pins = "PI14", "PI13", "PI12",
						 "PI11", "PI10", "PI9";
				allwinner,function = "io_disabled";
				allwinner,muxsel = <7>;
				allwinner,drive = <1>;
				allwinner,pull = <1>;
			};

			daudio0_pins_a: daudio0@0 {
				allwinner,pins = "PB4", "PB5", "PB6", "PB7", "PB8";
				allwinner,function = "pcm0";
				allwinner,muxsel = <3>;
				allwinner,drive = <1>;
				allwinner,pull = <0>;
			};

			daudio0_pins_b: daudio0_sleep@0 {
				allwinner,pins = "PB4", "PB5", "PB6", "PB7", "PB8";
				allwinner,function = "io_disabled";
				allwinner,muxsel = <7>;
				allwinner,drive = <1>;
				allwinner,pull = <0>;
			};

			daudio1_pins_a: daudio1@0 {
				allwinner,pins = "PG9", "PG10", "PG11", "PG12", "PG13";
				allwinner,function = "pcm1";
				allwinner,muxsel = <3>;
				allwinner,drive = <1>;
				allwinner,pull = <0>;
			};

			daudio1_pins_b: daudio1_sleep@0 {
				allwinner,pins = "PG9", "PG10", "PG11", "PG12", "PG13";
				allwinner,function = "io_disabled";
				allwinner,muxsel = <7>;
				allwinner,drive = <1>;
				allwinner,pull = <0>;
			};

			daudio2_pins_a: daudio2@0 {
				allwinner,pins = "PE5", "PE6", "PE7", "PE8", "PE9";
				allwinner,function = "pcm2";
				allwinner,muxsel = <4>;
				allwinner,drive = <1>;
				allwinner,pull = <0>;
			};

			daudio2_pins_b: daudio2_sleep@0 {
				allwinner,pins = "PE5", "PE6", "PE7", "PE8", "PE9";
				allwinner,function = "io_disabled";
				allwinner,muxsel = <7>;
				allwinner,drive = <1>;
				allwinner,pull = <0>;
			};

			daudio3_pins_a: daudio3@0 {
					allwinner,pins = "PH13", "PH14", "PH15", "PH16", "PH17", "PH18", "PH19";
					allwinner,function = "pcm3";
					allwinner,muxsel = <4>;
					allwinner,drive = <1>;
					allwinner,pull = <0>;
			};

			daudio3_pins_b: daudio3_sleep@0 {
					allwinner,pins = "PH13", "PH14", "PH15", "PH16", "PH17", "PH18", "PH19";
					allwinner,function = "io_disabled";
					allwinner,muxsel = <7>;
					allwinner,drive = <1>;
					allwinner,pull = <0>;
			};

			spdif_pins_a: spdif@0 {
				allwinner,pins = "PH6", "PH7";
				allwinner,function = "spdif";
				allwinner,muxsel = <4>;
				allwinner,drive = <1>;
				allwinner,pull = <0>;
			};

			spdif_pins_b: spdif_sleep@0 {
				allwinner,pins = "PH6", "PH7";
				allwinner,function = "io_disabled";
				allwinner,muxsel = <7>;
				allwinner,drive = <1>;
				allwinner,pull = <0>;
			};

			dmic_pins_a: dmic@0 {
				allwinner,pins = "PH8", "PH9", "PH10", "PH11", "PH12";
				allwinner,function = "dmic";
				allwinner,muxsel = <2>;
				allwinner,drive = <1>;
				allwinner,pull = <0>;
			};

			dmic_pins_b: dmic_sleep@0 {
				allwinner,pins = "PH8", "PH9", "PH10", "PH11", "PH12";
				allwinner,function = "io_disabled";
				allwinner,muxsel = <7>;
				allwinner,drive = <1>;
				allwinner,pull = <0>;
			};

			csi_mclk0_pins_a: csi_mclk0@0 {
				allwinner,pins = "PE0";
				allwinner,pname = "csi_mclk0";
				allwinner,function = "csi_mclk0";
				allwinner,muxsel = <2>;
				allwinner,drive = <2>;
				allwinner,pull = <0>;
			};
			csi_mclk0_pins_b: csi_mclk0@1 {
				allwinner,pins = "PE0";
				allwinner,pname = "csi_mclk0";
				allwinner,function = "io_disabled";
				allwinner,muxsel = <7>;
				allwinner,drive = <2>;
				allwinner,pull = <0>;
			};
			csi_mclk1_pins_a: csi_mclk1@0 {
				allwinner,pins = "PE5";
				allwinner,pname = "csi_mclk1";
				allwinner,function = "csi_mclk1";
				allwinner,muxsel = <2>;
				allwinner,drive = <2>;
				allwinner,pull = <0>;
			};
			csi_mclk1_pins_b: csi_mclk1@1 {
				allwinner,pins = "PE5";
				allwinner,pname = "csi_mclk1";
				allwinner,function = "io_disabled";
				allwinner,muxsel = <7>;
				allwinner,drive = <2>;
				allwinner,pull = <0>;
			};

			scr0_pins_a: scr0@0 {
				allwinner,pins = "PG13", "PG14", "PG10", "PG11", "PG12";
				allwinner,pname = "scr0_rst", "scr0_det", "scr0_vccen", "scr0_sck", "scr0_sda";
				allwinner,function = "sim0";
				allwinner,muxsel = <4>;
				allwinner,drive = <0>;
				allwinner,pull = <1>;
			};

			scr0_pins_b: scr0@1 {
				allwinner,pins = "PG8", "PG9";
				allwinner,pname = "scr0_vppen", "scr0_vppp";
				allwinner,function = "sim0";
				allwinner,muxsel = <4>;
				allwinner,drive = <0>;
				allwinner,pull = <1>;
			};

			scr0_pins_c: scr0@2 {
				allwinner,pins = "PG8", "PG9", "PG10", "PG11", "PG12", "PG13", "PG14";
				allwinner,function = "io_disabled";
				allwinner,muxsel = <7>;
				allwinner,drive = <0>;
				allwinner,pull = <0>;
			};

			scr1_pins_a: scr1@0 {
				allwinner,pins = "PH5", "PH6", "PH2",
						 "PH3", "PH4";
				allwinner,pname = "scr1_rst", "scr1_det",
						  "scr1_vccen", "scr1_sck",
						  "scr1_sda";
				allwinner,function = "sim1";
				allwinner,muxsel = <5>;
				allwinner,drive = <1>;
				allwinner,pull = <1>;
			};

			scr1_pins_b: scr1@1 {
				allwinner,pins = "PH0", "PH1";
				allwinner,pname = "scr1_vppen", "scr1_vppp";
				allwinner,function = "sim1";
				allwinner,muxsel = <5>;
				allwinner,drive = <1>;
				allwinner,pull = <1>;
			};

			scr1_pins_c: scr1@2 {
				allwinner,pins = "PH0", "PH1", "PH2",
						 "PH3", "PH4", "PH5",
						 "PH6";
				allwinner,function = "io_disabled";
				allwinner,muxsel = <7>;
				allwinner,drive = <1>;
				allwinner,pull = <0>;
			};

			nand0_pins_a: nand0@0 {
				allwinner,pins = "PC0", "PC1", "PC2", "PC4",
						 "PC6", "PC7", "PC8", "PC9",
						 "PC10", "PC11", "PC12", "PC13",
						 "PC14";
				allwinner,pname= "nand0_we", "nand0_ale","nand0_cle", "nand0_nre",
						 "nand0_d0", "nand0_d1", "nand0_d2", "nand0_d3",
						 "nand0_d4", "nand0_d5", "nand0_d6", "nand0_d7",
						 "nand0_ndqs";
				allwinner,function = "nand0";
				allwinner,muxsel = <2>;
				allwinner,drive = <1>;
				allwinner,pull = <0>;
			};

			nand0_pins_b: nand0@1 {
				allwinner,pins = "PC3", "PC5", "PC15", "PC16";
				allwinner,pname= "nand0_ce0", "nand0_rb0", "nand0_ce1", "nand0_rb1";
				allwinner,function = "nand0";
				allwinner,muxsel = <2>;
				allwinner,drive = <1>;
				allwinner,pull = <1>;	/* only RB&CE should be pulled up */
			};

			nand0_pins_c: nand0@2 {
				allwinner,pins = "PC0", "PC1", "PC2", "PC3",
						 "PC4", "PC5", "PC6", "PC7",
						 "PC8", "PC9", "PC10", "PC11",
						 "PC12", "PC13", "PC14", "PC15",
						 "PC16";
				allwinner,function = "io_disabled";
				allwinner,muxsel = <7>;
				allwinner,drive = <1>;
				allwinner,pull = <0>;
			};

			ccir_clk_pin_a: ac200@2 {
				allwinner,pins = "PB0";
				allwinner,function = "ac200";
				allwinner,muxsel = <2>;
				allwinner,drive = <1>;
				allwinner,pull = <0>;
			};

			ccir_clk_pin_b: ac200@3 {
				allwinner,pins = "PB0";
				allwinner,function = "io_disabled";
				allwinner,muxsel = <7>;
				allwinner,drive = <1>;
				allwinner,pull = <0>;
			};

			gmac_pins_a: gmac@0 {
				allwinner,pins = "PH0", "PH1", "PH2", "PH3",
						 "PH4", "PH5", "PH6", "PH7",
						 "PH9", "PH10", "PH13", "PH14",
						 "PH15", "PH16", "PH17", "PH18";
				allwinner,function = "gmac0";
				allwinner,muxsel = <5>;
				allwinner,drive = <3>;
				allwinner,pull = <0>;
			};

			gmac_pins_b: gmac@1 {
				allwinner,pins = "PH0", "PH1", "PH2", "PH3",
						 "PH4", "PH5", "PH6", "PH7",
						 "PH9", "PH10", "PH13", "PH14",
						 "PH15", "PH16", "PH17", "PH18";
				allwinner,function = "io_disabled";
				allwinner,muxsel = <7>;
				allwinner,drive = <3>;
				allwinner,pull = <0>;
			};

			gmac1_pins_a: gmac1@0 {
				allwinner,pins = "PJ0", "PJ1", "PJ2", "PJ3",
						 "PJ4", "PJ5", "PJ6", "PJ7",
						 "PJ8", "PJ9", "PJ10", "PJ11",
						 "PJ12", "PJ13", "PJ14", "PJ15";
				allwinner,function = "gmac1";
				allwinner,muxsel = <5>;
				allwinner,drive = <3>;
				allwinner,pull = <0>;
			};

			gmac1_pins_b: gmac1@1 {
				allwinner,pins = "PJ0", "PJ1", "PJ2", "PJ3",
						 "PJ4", "PJ5", "PJ6", "PJ7",
						 "PJ8", "PJ9", "PJ10", "PJ11",
						 "PJ12", "PJ13", "PJ14", "PJ15";
				allwinner,function = "io_disabled";
				allwinner,muxsel = <7>;
				allwinner,drive = <3>;
				allwinner,pull = <0>;
			};

			ledc_pins_a: ledc@0 {
				allwinner,pins = "PH19";
				allwinner,function = "ledc";
				allwinner,muxsel = <5>;
				allwinner,drive = <1>;
				allwinner,pull = <1>;
			};

			ledc_pins_b: ledc@1 {
				allwinner,pins = "PH19";
				allwinner,function = "io_disabled";
				allwinner,muxsel = <7>;
				allwinner,drive = <1>;
				allwinner,pull = <0>;
			};
			lvds0_pins_a: lvds0@0 {
				allwinner,pins = "PD0", "PD1", "PD2", "PD3", "PD4", "PD5", "PD8", "PD9", "PD6", "PD7";
				allwinner,pname = "PD0", "PD1", "PD2", "PD3", "PD4", "PD5", "PD8", "PD9", "PD6", "PD7";
				allwinner,function = "lvds0";
				allwinner,muxsel = <3>;
				allwinner,drive = <3>;
				allwinner,pull = <0>;
			};
			lvds0_pins_b: lvds0@1 {
				allwinner,pins = "PD0", "PD1", "PD2", "PD3", "PD4", "PD5", "PD8", "PD9", "PD6", "PD7";
				allwinner,pname = "PD0", "PD1", "PD2", "PD3", "PD4", "PD5", "PD8", "PD9", "PD6", "PD7";
				allwinner,function = "lvds0_suspend";
				allwinner,muxsel = <7>;
				allwinner,drive = <3>;
				allwinner,pull = <0>;
			};

			lvds1_pins_a: lvds1@0 {
				allwinner,pins = "PD10", "PD11", "PD12", "PD13", "PD14", "PD15", "PD18", "PD19", "PD16", "PD17";
				allwinner,pname = "PD10", "PD11", "PD12", "PD13", "PD14", "PD15", "PD18", "PD19", "PD16", "PD17";
				allwinner,function = "lvds1";
				allwinner,muxsel = <3>;
				allwinner,drive = <3>;
				allwinner,pull = <0>;
			};
			lvds1_pins_b: lvds1@1 {
				allwinner,pins = "PD10", "PD11", "PD12", "PD13", "PD14", "PD15", "PD18", "PD19", "PD16", "PD17";
				allwinner,pname = "PD10", "PD11", "PD12", "PD13", "PD14", "PD15", "PD18", "PD19", "PD16", "PD17";
				allwinner,function = "lvds1_suspend";
				allwinner,muxsel = <7>;
				allwinner,drive = <3>;
				allwinner,pull = <0>;
			};

			lvds2_pins_a: lvds2@0 {
				allwinner,pins = "PJ7", "PJ6", "PJ5", "PJ4", "PJ3", "PJ2", "PJ1", "PJ0", "PJ8", "PJ9";
				allwinner,pname = "PJ7", "PJ6", "PJ5", "PJ4", "PJ3", "PJ2", "PJ1", "PJ0", "PJ8", "PJ9";
				allwinner,function = "lvds2";
				allwinner,muxsel = <3>;
				allwinner,drive = <3>;
				allwinner,pull = <0>;
			};
			lvds2_pins_b: lvds2@1 {
				allwinner,pins = "PJ7", "PJ6", "PJ5", "PJ4", "PJ3", "PJ2", "PJ1", "PJ0", "PJ8", "PJ9";
				allwinner,pname = "PJ7", "PJ6", "PJ5", "PJ4", "PJ3", "PJ2", "PJ1", "PJ0", "PJ8", "PJ9";
				allwinner,function = "lvds2_suspend";
				allwinner,muxsel = <7>;
				allwinner,drive = <3>;
				allwinner,pull = <0>;
			};

			lvds3_pins_a: lvds3@0 {
				allwinner,pins = "PJ10", "PJ11", "PJ12", "PJ13", "PJ14", "PJ15", "PJ16", "PJ17", "PJ18", "PJ19";
				allwinner,pname = "PJ10", "PJ11", "PJ12", "PJ13", "PJ14", "PJ15", "PJ16", "PJ17", "PJ18", "PJ19";
				allwinner,function = "lvds3";
				allwinner,muxsel = <3>;
				allwinner,drive = <3>;
				allwinner,pull = <0>;
			};

			lvds3_pins_b: lvds3@1 {
				allwinner,pins = "PJ10", "PJ11", "PJ12", "PJ13", "PJ14", "PJ15", "PJ16", "PJ17", "PJ18", "PJ19";
				allwinner,pname = "PJ10", "PJ11", "PJ12", "PJ13", "PJ14", "PJ15", "PJ16", "PJ17", "PJ18", "PJ19";
				allwinner,function = "lvds3_suspend";
				allwinner,muxsel = <7>;
				allwinner,drive = <3>;
				allwinner,pull = <0>;
			};

			lcd1_lvds2link_pins_a: lcd1_lvds2link@0 {
				allwinner,pins = "PJ10", "PJ11", "PJ12", "PJ13", "PJ14", "PJ15", "PJ16", "PJ17", "PJ18", "PJ19", \
				"PJ7", "PJ6", "PJ5", "PJ4", "PJ3", "PJ2", "PJ1", "PJ0", "PJ8", "PJ9";
				allwinner,pname = "PJ10", "PJ11", "PJ12", "PJ13", "PJ14", "PJ15", "PJ16", "PJ17", "PJ18", "PJ19", \
				"PJ7", "PJ6", "PJ5", "PJ4", "PJ3", "PJ2", "PJ1", "PJ0", "PJ8", "PJ9";
				allwinner,function = "lvds3";
				allwinner,muxsel = <3>;
				allwinner,drive = <3>;
				allwinner,pull = <0>;
			};

			lcd1_lvds2link_pins_b: lcd1_lvds2link@1 {
				allwinner,pins = "PJ10", "PJ11", "PJ12", "PJ13", "PJ14", "PJ15", "PJ16", "PJ17", "PJ18", "PJ19", \
				"PJ7", "PJ6", "PJ5", "PJ4", "PJ3", "PJ2", "PJ1", "PJ0", "PJ8", "PJ9";
				allwinner,pname = "PJ10", "PJ11", "PJ12", "PJ13", "PJ14", "PJ15", "PJ16", "PJ17", "PJ18", "PJ19", \
				"PJ7", "PJ6", "PJ5", "PJ4", "PJ3", "PJ2", "PJ1", "PJ0", "PJ8", "PJ9";
				allwinner,function = "lvds3_suspend";
				allwinner,muxsel = <7>;
				allwinner,drive = <3>;
				allwinner,pull = <0>;
			};

			lvds2link_pins_a: lvds2link@0 {
				allwinner,pins = "PD0", "PD1", "PD2", "PD3", "PD4", "PD5", "PD8", "PD9", "PD6", "PD7", \
				"PD10", "PD11", "PD12", "PD13", "PD14", "PD15", "PD18", "PD19", "PD16", "PD17";
				allwinner,pname = "PD0", "PD1", "PD2", "PD3", "PD4", "PD5", "PD8", "PD9", "PD6", "PD7", \
				"PD10", "PD11", "PD12", "PD13", "PD14", "PD15", "PD18", "PD19", "PD16", "PD17";
				allwinner,function = "lvds2link";
				allwinner,muxsel = <3>;
				allwinner,drive = <3>;
				allwinner,pull = <0>;
			};
			lvds2link_pins_b: lvds2link@1 {
				allwinner,pins = "PD0", "PD1", "PD2", "PD3", "PD4", "PD5", "PD8", "PD9", "PD6", "PD7", \
				"PD10", "PD11", "PD12", "PD13", "PD14", "PD15", "PD18", "PD19", "PD16", "PD17";
				allwinner,pname = "PD0", "PD1", "PD2", "PD3", "PD4", "PD5", "PD8", "PD9", "PD6", "PD7", \
				"PD10", "PD11", "PD12", "PD13", "PD14", "PD15", "PD18", "PD19", "PD16", "PD17";
				allwinner,function = "lvds2link_suspend";
				allwinner,muxsel = <7>;
				allwinner,drive = <3>;
				allwinner,pull = <0>;
			};

			rgb24_pins_a: rgb24@0 {
				allwinner,pins = "PD0", "PD1", "PD2", "PD3", "PD4", "PD5", "PD6", "PD7", "PD8", "PD9", \
				"PD10", "PD11", "PD12", "PD13", "PD14", "PD15", "PD16", "PD17", "PD18", "PD19", \
				"PD20", "PD21", "PD22", "PD23", "PD24", "PD25", "PD26", "PD27";
				allwinner,pname = "PD0", "PD1", "PD2", "PD3", "PD4", "PD5", "PD6", "PD7", "PD8", "PD9", \
				"PD10", "PD11", "PD12", "PD13", "PD14", "PD15", "PD16", "PD17", "PD18", "PD19", \
				"PD20", "PD21", "PD22", "PD23", "PD24", "PD25", "PD26", "PD27";
				allwinner,function = "rgb24";
				allwinner,muxsel = <2>;
				allwinner,drive = <3>;
				allwinner,pull = <0>;
			};
			rgb24_pins_b: rgb24@1 {
				allwinner,pins = "PD0", "PD1", "PD2", "PD3", "PD4", "PD5", "PD6", "PD7", "PD8", "PD9", \
				"PD10", "PD11", "PD12", "PD13", "PD14", "PD15", "PD16", "PD17", "PD18", "PD19", \
				"PD20", "PD21", "PD22", "PD23", "PD24", "PD25", "PD26", "PD27";
				allwinner,pname = "PD0", "PD1", "PD2", "PD3", "PD4", "PD5", "PD6", "PD7", "PD8", "PD9", \
				"PD10", "PD11", "PD12", "PD13", "PD14", "PD15", "PD16", "PD17", "PD18", "PD19", \
				"PD20", "PD21", "PD22", "PD23", "PD24", "PD25", "PD26", "PD27";
				allwinner,function = "rgb24_suspend";
				allwinner,muxsel = <7>;
				allwinner,drive = <3>;
				allwinner,pull = <0>;
			};
			rgb18_pins_a: rgb18@0 {
				allwinner,pins = "PD0", "PD1", "PD2", "PD3", "PD4", "PD5", "PD6", "PD7", "PD8", "PD9", \
				"PD10", "PD11", "PD12", "PD13", "PD14", "PD15", "PD16", "PD17", "PD18", "PD19", \
				"PD20", "PD21";
				allwinner,pname = "PD0", "PD1", "PD2", "PD3", "PD4", "PD5", "PD6", "PD7", "PD8", "PD9", \
				"PD10", "PD11", "PD12", "PD13", "PD14", "PD15", "PD16", "PD17", "PD18", "PD19", \
				"PD20", "PD21";
				allwinner,function = "rgb18";
				allwinner,muxsel = <2>;
				allwinner,drive = <3>;
				allwinner,pull = <0>;
			};
			rgb18_pins_b: rgb18@1 {
				allwinner,pins = "PD0", "PD1", "PD2", "PD3", "PD4", "PD5", "PD6", "PD7", "PD8", "PD9", \
				"PD10", "PD11", "PD12", "PD13", "PD14", "PD15", "PD16", "PD17", "PD18", "PD19", \
				"PD20", "PD21";
				allwinner,pname = "PD0", "PD1", "PD2", "PD3", "PD4", "PD5", "PD6", "PD7", "PD8", "PD9", \
				"PD10", "PD11", "PD12", "PD13", "PD14", "PD15", "PD16", "PD17", "PD18", "PD19", \
				"PD20", "PD21";
				allwinner,function = "rgb18_suspend";
				allwinner,muxsel = <7>;
				allwinner,drive = <1>;
				allwinner,pull = <0>;
			};

			eink_pins_a: eink@0 {
				allwinner,pins = "PD0", "PD1", "PD2", "PD3", "PD4", "PD5", "PD6", "PD7", "PD8", "PD9", \
				"PD10", "PD11", "PD12", "PD13", "PD14", "PD15", "PD16", "PD17", "PD18", "PD19", \
				"PD20", "PD21", "PD22";
				allwinner,pname = "eink_pin0", "eink_pin1", "eink_pin2", "eink_pin3", "eink_pin4", \
						  "eink_pin5", "eink_pin6", "eink_pin7", "eink_pin8", "eink_pin9", \
						  "eink_pin10", "eink_pin11", "eink_pin12", "eink_pin13", "eink_pin14", \
						  "eink_pin15", "eink_pinoeh", "eink_pinleh", "eink_pinckh", "eink_pinsth", \
						  "eink_pinckv", "eink_pinmod", "eink_pinstv";
				allwinner,function = "eink";
				allwinner,muxsel = <5>;
				allwinner,drive = <3>;
				allwinner,pull = <0>;
			};
			eink_pins_b: eink@1 {
				allwinner,pins = "PD0", "PD1", "PD2", "PD3", "PD4", "PD5", "PD6", "PD7", "PD8", "PD9", \
				"PD10", "PD11", "PD12", "PD13", "PD14", "PD15", "PD16", "PD17", "PD18", "PD19", \
				"PD20", "PD21", "PD22";
				allwinner,pname = "eink_pin0", "eink_pin1", "eink_pin2", "eink_pin3", "eink_pin4", \
						  "eink_pin5", "eink_pin6", "eink_pin7", "eink_pin8", "eink_pin9", \
						  "eink_pin10", "eink_pin11", "eink_pin12", "eink_pin13", "eink_pin14", \
						  "eink_pin15", "eink_pinoeh", "eink_pinleh", "eink_pinckh", "eink_pinsth", \
						  "eink_pinckv", "eink_pinmod", "eink_pinstv";
				allwinner,function = "eink_suspend";
				allwinner,muxsel = <7>;
				allwinner,drive = <1>;
				allwinner,pull = <0>;
			};
			dsi4lane_pins_a: dsi4lane@0 {
				allwinner,pins = "PD0", "PD1", "PD2", "PD3", "PD4", "PD5", "PD6", "PD7", "PD8", "PD9";
				allwinner,pname = "PD0", "PD1", "PD2", "PD3", "PD4", "PD5", "PD6", "PD7", "PD8", "PD9";
				allwinner,function = "dsi4lane";
				allwinner,muxsel = <4>;
				allwinner,drive = <3>;
				allwinner,pull = <0>;
			};
			dsi4lane_pins_b: dsi4lane@1 {
				allwinner,pins = "PD0", "PD1", "PD2", "PD3", "PD4", "PD5", "PD6", "PD7", "PD8", "PD9";
				allwinner,pname = "PD0", "PD1", "PD2", "PD3", "PD4", "PD5", "PD6", "PD7", "PD8", "PD9";
				allwinner,function = "dsi4lane_suspend";
				allwinner,muxsel = <7>;
				allwinner,drive = <1>;
				allwinner,pull = <0>;
			};

			pwm0_pin_a: pwm0@0 {
				allwinner,pins = "PD23";
				allwinner,function = "pwm0";
				allwinner,muxsel = <0x02>;
				allwinner,drive = <0x2>;
				allwinner,pull = <0>;
				allwinner,data = <0xffffffff>;
			};

			pwm0_pin_b: pwm0@1 {
				allwinner,pins = "PD23";
				allwinner,function = "io_disabled";
				allwinner,muxsel = <0x07>;
				allwinner,drive = <0x2>;
				allwinner,pull = <0>;
				allwinner,data = <0xffffffff>;
			};

			pwm1_pin_a: pwm1@0 {
				allwinner,pins = "PD22";
				allwinner,function = "pwm1";
				allwinner,muxsel = <0x02>;
				allwinner,drive = <0x2>;
				allwinner,pull = <0>;
				allwinner,data = <0xffffffff>;
			};

			pwm1_pin_b: pwm1@1 {
				allwinner,pins = "PD22";
				allwinner,function = "io_disabled";
				allwinner,muxsel = <0x07>;
				allwinner,drive = <0x2>;
				allwinner,pull = <0>;
				allwinner,data = <0xffffffff>;
			};

			pwm2_pin_a: pwm2@0 {
				allwinner,pins = "PD20";
				allwinner,function = "pwm2";
				allwinner,muxsel = <0x02>;
				allwinner,drive = <0x2>;
				allwinner,pull = <0>;
				allwinner,data = <0xffffffff>;
			};

			pwm2_pin_b: pwm2@1 {
				allwinner,pins = "PD20";
				allwinner,function = "io_disabled";
				allwinner,muxsel = <0x07>;
				allwinner,drive = <0x2>;
				allwinner,pull = <0>;
				allwinner,data = <0xffffffff>;
			};

			pwm3_pin_a: pwm3@0 {
				allwinner,pins = "PD21";
				allwinner,function = "pwm3";
				allwinner,muxsel = <0x02>;
				allwinner,drive = <0x2>;
				allwinner,pull = <0>;
				allwinner,data = <0xffffffff>;
			};

			pwm3_pin_b: pwm3@1 {
				allwinner,pins = "PD21";
				allwinner,function = "io_disabled";
				allwinner,muxsel = <0x07>;
				allwinner,drive = <0x2>;
				allwinner,pull = <0>;
				allwinner,data = <0xffffffff>;
			};

			usb1_vbus_pin_a: usb1_vbus_pin@0 {
				allwinner,pins = "PH10";
				allwinner,function = "gpio_out";
				allwinner,muxsel = <0x01>;
				allwinner,drive = <0x2>;
				allwinner,pull = <0>;
				allwinner,data = <0x0>;
			};

			card0_boot_pin: card0_boot_para@0 {
				allwinner,pins = "PF0", "PF1", "PF2", "PF3", "PF4", "PF5";
				allwinner,function = "card0_boot_para";
				allwinner,pname = "sdc_d1", "sdc_d0", "sdc_clk", "sdc_cmd", "sdc_d3", "sdc_d2";
				allwinner,muxsel = <0x2>;
				allwinner,pull = <0x1>;
				allwinner,drive = <0x3>;
				allwinner,data = <0xffffffff>;
			};

			card2_boot_pin_a: card2_boot_para@0 {
				allwinner,pins = "PC5", "PC6", "PC10", "PC13", "PC15", "PC8", "PC9", "PC11", "PC14", "PC16", "PC1";
				allwinner,function = "card2_boot_para";
				allwinner,pname = "sdc_clk", "sdc_cmd", "sdc_d0", "sdc_d1", "sdc_d2", "sdc_d3", "sdc_d4", "sdc_d5", "sdc_d6", "sdc_d7", "sdc_emmc_rst";
				allwinner,muxsel = <0x3>;
				allwinner,pull = <0x1>;
				allwinner,drive = <0x3>;
				allwinner,data = <0xffffffff>;
			};

			card2_boot_pin_b: card2_boot_para@1 {
				allwinner,pins = "PC0";
				allwinner,function = "card2_boot_para";
				allwinner,pname = "sdc_ds";
				allwinner,muxsel = <0x3>;
				allwinner,pull = <0x2>;
				allwinner,drive = <0x3>;
				allwinner,data = <0xffffffff>;
			};

			twi_para@0 {
				allwinner,pins = "PH14", "PH15";
				allwinner,function = "twi_para";
				allwinner,pname = "twi_scl", "twi_sda";
				allwinner,muxsel = <0x2>;
				allwinner,pull = <0xffffffff>;
				allwinner,drive = <0xffffffff>;
				allwinner,data = <0xffffffff>;
			};

			uart_para@0 {
				allwinner,pins = "PB9", "PB10";
				allwinner,function = "uart_para";
				allwinner,pname = "uart_debug_tx", "uart_debug_rx";
				allwinner,muxsel = <0x2>;
				allwinner,pull = <0x1>;
				allwinner,drive = <0xffffffff>;
				allwinner,data = <0xffffffff>;
			};

			jtag_para@0 {
				allwinner,pins = "PH9", "PH10", "PH11", "PH12";
				allwinner,function = "jtag_para";
				allwinner,pname = "jtag_ms", "jtag_ck", "jtag_do", "jtag_di";
				allwinner,muxsel = <0x3>;
				allwinner,pull = <0xffffffff>;
				allwinner,drive = <0xffffffff>;
				allwinner,data = <0xffffffff>;
			};
		};

		dma0:dma-controller@03002000 {
			compatible = "allwinner,sun50i-dma";
			reg = <0x0 0x03002000 0x0 0x1000>;
			interrupts = <GIC_SPI 45 IRQ_TYPE_LEVEL_HIGH>;
			clocks = <&clk_dma>;
			#dma-cells = <1>;
		};

		nsi0:nsi-controller@03100000 {
			compatible = "allwinner,sun50i-nsi";
			interrupts = <GIC_SPI 63 IRQ_TYPE_LEVEL_HIGH>;
			reg = <0x0 0x03100000 0x0 0x10000>;
			clocks = <&clk_pll_ddr>, <&clk_mbus>;
			clock-frequency = <448000000>;
			#nsi-cells = <1>;
			status = "okay";
			cpu{
				mode = <0>; /*dont't set cpu mode*/
				pri = <0>;
				select = <0>;
			};
			gpu{
				mode = <0>;
				pri = <3>;
				select = <1>;
			};
			sd1{
				mode = <1>;
				pri = <2>;
				select = <0>;
			};
			mstg{
				mode = <0>;
				pri = <1>;
				select = <0>;
			};
			ce{
				mode = <1>;
				pri = <0>;
				select = <1>;
			};
		};

		mbus0:mbus-controller@047fa000 {
			compatible = "allwinner,sun50i-mbus";
			reg = <0x0 0x047fa000 0x0 0x1000>;
			#mbus-cells = <1>;
		};

		arisc {
			compatible = "allwinner,sunxi-arisc";
			#address-cells = <2>;
			#size-cells = <2>;
			clocks = <&clk_losc>, <&clk_iosc>, <&clk_hosc>, <&clk_pll_periph0>;
			clock-names = "losc", "iosc", "hosc", "pll_periph0";
			powchk_used = <0x0>;
			power_reg = <0x02309621>;
			system_power = <50>;
		};

		arisc_space {
			compatible = "allwinner,arisc_space";
			/* num    dst        offset     size                              */
			space1 = <0x48040000 0x00000000 0x00014000>; /* srama2 code space */
			space2 = <0x48100000 0x00018000 0x00004000>; /* dram code space   */
			space3 = <0x48104000 0x00000000 0x00001000>; /* para space        */
			space4 = <0x48105000 0x00000000 0x00001000>; /* msgpool space     */
		};

		standby_space {
			compatible = "allwinner,sun50iw10-usbstandby";
			/* num    dst        offset     size						*/
			space1 = <0x40020000 0x00000000 0x00000800>; /* super standby para space        */
		};

		msgbox: msgbox@03003000 {
			compatible = "allwinner,msgbox";
			clocks = <&clk_msgbox>;
			clock-names = "clk_msgbox";
			reg = <0x0 0x03003000 0x0 0x1000>;
			interrupts = <GIC_SPI 46 IRQ_TYPE_EDGE_RISING>;
			status = "okay";
		};

		s_cir0: s_cir@07040000 {
			compatible = "allwinner,s_cir";
			reg = <0x0 0x07040000 0x0 0x400>;
			interrupts = <GIC_SPI 115 IRQ_TYPE_LEVEL_HIGH>;
			pinctrl-names = "default";
			pinctrl-0 = <&s_cir0_pins_a>;
			clocks = <&clk_hosc>,<&clk_cpurcir>;
			status = "okay";
		};

		ir1: ir@0x05071000 {
			compatible = "allwinner,ir_tx";
			reg = <0x0 0x05071000 0x0 0x400>;
			interrupts = <GIC_SPI 19 IRQ_TYPE_LEVEL_HIGH>;
			pinctrl-names = "default","sleep";
			pinctrl-0 = <&ir0_pins_a>,<&ir0_pins_b>;
			clocks = <&clk_hosc>,<&clk_irtx>;
			status = "okay";
		};

		soc_timer0: timer@03009000 {
			compatible = "allwinner,sun4i-a10-timer";
			device_type = "soc_timer";
			reg = <0x0 0x03009000 0x0 0x400>;
			interrupts = <GIC_SPI 51 IRQ_TYPE_LEVEL_HIGH>;
			clocks = <&clk_hosc>;
		};

		rtc: rtc@07000000 {
			compatible = "allwinner,sunxi-rtc";
			device_type = "rtc";
			wakeup-source;
			reg = <0x0 0x07000000 0x0 0x200>;
			interrupts = <GIC_SPI 108 IRQ_TYPE_LEVEL_HIGH>;
			gpr_offset = <0x100>;
			gpr_len	   = <8>;
			gpr_cur_pos = <6>;
		};

		wdt: watchdog@030090a0 {
			compatible = "allwinner,sun50i-wdt";
			reg = <0x0 0x030090a0 0x0 0x20>;
			interrupts = <GIC_SPI 53 IRQ_TYPE_LEVEL_HIGH>;
		};

		ve: ve@01c0e000 {
			compatible = "allwinner,sunxi-cedar-ve";
			reg = <0x0 0x01c0e000 0x0 0x1000>,
			      <0x0 0x03000000 0x0 0x10>,
			      <0x0 0x03001000 0x0 0x1000>;
			interrupts = <GIC_SPI 94 IRQ_TYPE_LEVEL_HIGH>;
			clocks = <&clk_pll_ve>,	<&clk_ve>;
			iommus = <&mmu_aw 2 1>;
		};

		vp9: vp9@01c00000 {
			compatible = "allwinner,sunxi-google-vp9";
			reg = <0x0 0x01c00000 0x0 0x1000>,
			      <0x0 0x03000000 0x0 0x10>,
			      <0x0 0x03001000 0x0 0x1000>;
			interrupts = <GIC_SPI 90 IRQ_TYPE_LEVEL_HIGH>;
			clocks = <&clk_pll_ve>;
			#clocks = <&clk_pll_periph0x2>;
		};

		uart0: uart@05000000 {
			compatible = "allwinner,sun50i-uart";
			device_type = "uart0";
			reg = <0x0 0x05000000 0x0 0x400>;
			interrupts = <GIC_SPI 0 IRQ_TYPE_LEVEL_HIGH>;
			clocks = <&clk_uart0>;
			pinctrl-names = "default", "sleep";
			pinctrl-0 = <&uart0_pins_a>;
			pinctrl-1 = <&uart0_pins_b>;
			uart0_port = <0>;
			uart0_type = <2>;
			status = "okay";
			uart-supply = <&reg_dcdc1>;
		};

		uart1: uart@05000400 {
			compatible = "allwinner,sun50i-uart";
			device_type = "uart1";
			reg = <0x0 0x05000400 0x0 0x400>;
			interrupts = <GIC_SPI 1 IRQ_TYPE_LEVEL_HIGH>;
			clocks = <&clk_uart1>;
			pinctrl-names = "default", "sleep";
			pinctrl-0 = <&uart1_pins_a>;
			pinctrl-1 = <&uart1_pins_b>;
			uart1_port = <1>;
			uart1_type = <4>;
			status = "disabled";
		};

		uart2: uart@05000800 {
			compatible = "allwinner,sun50i-uart";
			device_type = "uart2";
			reg = <0x0 0x05000800 0x0 0x400>;
			interrupts = <GIC_SPI 2 IRQ_TYPE_LEVEL_HIGH>;
			clocks = <&clk_uart2>;
			pinctrl-names = "default", "sleep";
			pinctrl-0 = <&uart2_pins_a>;
			pinctrl-1 = <&uart2_pins_b>;
			uart2_port = <2>;
			uart2_type = <4>;
			status = "disabled";
		};

		uart3: uart@05000c00 {
			compatible = "allwinner,sun50i-uart";
			device_type = "uart3";
			reg = <0x0 0x05000c00 0x0 0x400>;
			interrupts = <GIC_SPI 3 IRQ_TYPE_LEVEL_HIGH>;
			clocks = <&clk_uart3>;
			pinctrl-names = "default", "sleep";
			pinctrl-0 = <&uart3_pins_a>;
			pinctrl-1 = <&uart3_pins_b>;
			uart3_port = <3>;
			uart3_type = <4>;
			status = "disabled";
		};

		uart4: uart@05001000 {
			compatible = "allwinner,sun50i-uart";
			device_type = "uart4";
			reg = <0x0 0x05001000 0x0 0x400>;
			interrupts = <GIC_SPI 4 IRQ_TYPE_LEVEL_HIGH>;
			clocks = <&clk_uart4>;
			pinctrl-names = "default", "sleep";
			pinctrl-0 = <&uart4_pins_a>;
			pinctrl-1 = <&uart4_pins_b>;
			uart4_port = <4>;
			uart4_type = <4>;
			status = "disabled";
		};

		uart5: uart@05001400 {
			compatible = "allwinner,sun50i-uart";
			device_type = "uart5";
			reg = <0x0 0x05001400 0x0 0x400>;
			interrupts = <GIC_SPI 5 IRQ_TYPE_LEVEL_HIGH>;
			clocks = <&clk_uart5>;
			pinctrl-names = "default", "sleep";
			pinctrl-0 = <&uart5_pins_a>;
			pinctrl-1 = <&uart5_pins_b>;
			uart5_port = <5>;
			uart5_type = <4>;
			status = "disabled";
		};

		uart6: uart@05001800 {
			compatible = "allwinner,sun50i-uart";
			device_type = "uart6";
			reg = <0x0 0x05001800 0x0 0x400>;
			interrupts = <GIC_SPI 6 IRQ_TYPE_LEVEL_HIGH>;
			clocks = <&clk_uart6>;
			pinctrl-names = "default", "sleep";
			pinctrl-0 = <&uart6_pins_a>;
			pinctrl-1 = <&uart6_pins_b>;
			uart6_port = <6>;
			uart6_type = <4>;
			status = "disabled";
		};

		uart7: uart@07080000 {
			compatible = "allwinner,sun50i-uart";
			device_type = "uart7";
			reg = <0x0 0x07080000 0x0 0x400>;
			interrupts = <GIC_SPI 112 IRQ_TYPE_LEVEL_HIGH>;
			clocks = <&clk_suart>;
			pinctrl-names = "default", "sleep";
			pinctrl-0 = <&s_uart0_pins_a>;
			pinctrl-1 = <&s_uart0_pins_b>;
			uart7_port = <7>;
			uart7_type = <2>;
			status = "disabled";
		};

/*
		ir0: ir@0x05071000 {
			#address-cells = <1>;
			#size-cells = <0>;
			compatible = "allwinner,ir_tx";
			device_type = "ir0";
			reg = <0x0 0x05071000 0x0 0x400>;
			interrupts = <GIC_SPI 19 IRQ_TYPE_LEVEL_HIGH>;
			clocks = <&clk_hosc>, <&clk_irtx>;
			pinctrl-names = "default", "sleep";
			pinctrl-0 = <&ir0_pins_a>;
			pinctrl-1 = <&ir0_pins_b>;
			status = "okay";
		};
*/

		twi0: twi@0x05002000{
			#address-cells = <1>;
			#size-cells = <0>;
			compatible = "allwinner,sun50i-twi";
			device_type = "twi0";
			reg = <0x0 0x05002000 0x0 0x400>;
			interrupts = <GIC_SPI 7 IRQ_TYPE_LEVEL_HIGH>;
			clocks = <&clk_twi0>;
			clock-frequency = <400000>;
			pinctrl-names = "default", "sleep";
			pinctrl-0 = <&twi0_pins_a>;
			pinctrl-1 = <&twi0_pins_b>;
			status = "okay";
		};

		twi1: twi@0x05002400{
			#address-cells = <1>;
			#size-cells = <0>;
			compatible = "allwinner,sun50i-twi";
			device_type = "twi1";
			reg = <0x0 0x05002400 0x0 0x400>;
			interrupts = <GIC_SPI 8 IRQ_TYPE_LEVEL_HIGH>;
			clocks = <&clk_twi1>;
			clock-frequency = <200000>;
			pinctrl-names = "default", "sleep";
			pinctrl-0 = <&twi1_pins_a>;
			pinctrl-1 = <&twi1_pins_b>;
			status = "okay";
			ac107@36{
				compatible = "Allwinnertech,ac107_0";
				/*gpio-reset = <&pio PH 6 1 1 1 1>;*/
				reg = <0x36>;
				status = "okay";
			};
		};

		twi2: twi@0x05002800{
			#address-cells = <1>;
			#size-cells = <0>;
			compatible = "allwinner,sun50i-twi";
			device_type = "twi2";
			reg = <0x0 0x05002800 0x0 0x400>;
			interrupts = <GIC_SPI 9 IRQ_TYPE_LEVEL_HIGH>;
			clocks = <&clk_twi2>;
			clock-frequency = <200000>;
			pinctrl-names = "default", "sleep";
			pinctrl-0 = <&twi2_pins_a>;
			pinctrl-1 = <&twi2_pins_b>;
			twi-supply = <&reg_dldo2>;
			status = "okay";
		};

		twi3: twi@0x05002c00{
			#address-cells = <1>;
			#size-cells = <0>;
			compatible = "allwinner,sun50i-twi";
			device_type = "twi3";
			reg = <0x0 0x05002c00 0x0 0x400>;
			interrupts = <GIC_SPI 10 IRQ_TYPE_LEVEL_HIGH>;
			clocks = <&clk_twi3>;
			clock-frequency = <200000>;
			pinctrl-names = "default", "sleep";
			pinctrl-0 = <&twi3_pins_a>;
			pinctrl-1 = <&twi3_pins_b>;
			twi-supply = <&reg_dldo2>;
			status = "okay";
		};

		twi4: twi@0x05003000{
			#address-cells = <1>;
			#size-cells = <0>;
			compatible = "allwinner,sun50i-twi";
			device_type = "twi4";
			reg = <0x0 0x05003000 0x0 0x400>;
			interrupts = <GIC_SPI 11 IRQ_TYPE_LEVEL_HIGH>;
			clocks = <&clk_twi4>;
			clock-frequency = <100000>;
			pinctrl-names = "default", "sleep";
			pinctrl-0 = <&twi4_pins_a>;
			pinctrl-1 = <&twi4_pins_b>;
			status = "disabled";
		};

		twi5: twi@0x05003400{
			#address-cells = <1>;
			#size-cells = <0>;
			compatible = "allwinner,sun50i-twi";
			device_type = "twi5";
			reg = <0x0 0x05003400 0x0 0x400>;
			interrupts = <GIC_SPI 12 IRQ_TYPE_LEVEL_HIGH>;
			clocks = <&clk_twi5>;
			clock-frequency = <100000>;
			pinctrl-names = "default", "sleep";
			pinctrl-0 = <&twi5_pins_a>;
			pinctrl-1 = <&twi5_pins_b>;
			status = "disabled";
		};

		twi6: s_twi@0x07081400 {
			#address-cells = <1>;
			#size-cells = <0>;
			compatible = "allwinner,sun50i-twi";
			reg = <0x0 0x07081400 0x0 0x200>;
			interrupts = <GIC_SPI 113 IRQ_TYPE_LEVEL_HIGH>;
			clocks = <&clk_stwi0>;
			clock-frequency = <200000>;
			pinctrl-names = "default", "sleep";
			pinctrl-0 = <&s_twi0_pins_a>;
			pinctrl-1 = <&s_twi0_pins_b>;
			twi_drv_used = <1>;
			no_suspend = <1>;
			status = "okay";

			pmu0: pmu@34 {
				compatible = "x-powers,axp803";
				reg = <0x34>;
				status = "okay";
				interrupts = <0 IRQ_TYPE_LEVEL_LOW>;
				interrupt-parent = <&nmi_intc>;
				x-powers,drive-vbus-en;
				pmu_reset = <0>;
				pmu_irq_wakeup = <1>;
				pmu_hot_shutdown = <1>;

				wakeup-source;

				ac_power_supply: ac-power-supply {
					compatible = "x-powers,axp803-ac-power-supply";
					status = "okay";

					pmu_ac_vol = <4600>;
					pmu_ac_cur = <3000>;

					wakeup_ac_in;
					wakeup_ac_out;
				};

				usb_power_supply: usb_power_supply {
					compatible = "x-powers,axp803-usb-power-supply";
					status = "okay";

					pmu_usbpc_vol = <4600>;
					/*
					 * debug conveniently, change usbpc_cur 1000
					 * should be restore 500 later
					 */
					pmu_usbpc_cur = <1000>;
					pmu_usbad_vol = <4600>;
					pmu_usbad_cur = <1500>;

					wakeup_usb_in;
					wakeup_usb_out;
				};

				battery_power_supply: battery-power-supply {
					compatible = "x-powers,axp803-battery-power-supply";
					status = "okay";

					pmu_chg_ic_temp = <0>;
					pmu_battery_rdc= <93>;
					pmu_battery_cap = <5067>;
					pmu_runtime_chgcur = <1000>;
					pmu_suspend_chgcur = <1500>;
					pmu_shutdown_chgcur = <1500>;
					pmu_init_chgvol = <4200>;
					pmu_battery_warning_level1 = <15>;
					pmu_battery_warning_level2 = <0>;
					pmu_chgled_type = <0>;
					pmu_bat_para1 = <0>;
					pmu_bat_para2 = <0>;
					pmu_bat_para3 = <0>;
					pmu_bat_para4 = <0>;
					pmu_bat_para5 = <6>;
					pmu_bat_para6 = <8>;
					pmu_bat_para7 = <9>;
					pmu_bat_para8 = <10>;
					pmu_bat_para9 = <11>;
					pmu_bat_para10 = <12>;
					pmu_bat_para11 = <13>;
					pmu_bat_para12 = <15>;
					pmu_bat_para13 = <18>;
					pmu_bat_para14 = <23>;
					pmu_bat_para15 = <29>;
					pmu_bat_para16 = <44>;
					pmu_bat_para17 = <50>;
					pmu_bat_para18 = <58>;
					pmu_bat_para19 = <65>;
					pmu_bat_para20 = <70>;
					pmu_bat_para21 = <75>;
					pmu_bat_para22 = <80>;
					pmu_bat_para23 = <83>;
					pmu_bat_para24 = <84>;
					pmu_bat_para25 = <86>;
					pmu_bat_para26 = <88>;
					pmu_bat_para27 = <90>;
					pmu_bat_para28 = <92>;
					pmu_bat_para29 = <95>;
					pmu_bat_para30 = <97>;
					pmu_bat_para31 = <98>;
					pmu_bat_para32 = <100>;

					wakeup_bat_out;
					/* wakeup_bat_in; */
					/* wakeup_bat_charging; */
					/* wakeup_bat_charge_over; */
					/* wakeup_low_warning1; */
					/* wakeup_low_warning2; */
					/* wakeup_bat_untemp_work; */
					/* wakeup_bat_ovtemp_work; */
					/* wakeup_bat_untemp_chg; */
					/* wakeup_bat_ovtemp_chg; */
				};

				powerkey0: powerkey@0 {
					status = "okay";
					compatible = "x-powers,axp2101-pek";
					pmu_powkey_off_time = <6000>;
					pmu_powkey_off_func = <0>;
					pmu_powkey_off_en = <1>;
					pmu_powkey_long_time = <1500>;
					pmu_powkey_on_time = <512>;
					wakeup_rising;
					/* wakeup_falling; */
				};

				regulator0: regulators@0 {
					reg_dcdc1: dcdc1 {
						regulator-name = "axp803-dcdc1";
						regulator-min-microvolt = <1600000>;
						regulator-max-microvolt = <3400000>;
						regulator-boot-on;
					};
					reg_dcdc2: dcdc2 {
						regulator-name = "axp803-dcdc2";
						regulator-min-microvolt = <500000>;
						regulator-max-microvolt = <1300000>;
						regulator-boot-on;
						regulator-always-on;
					};
					reg_dcdc3: dcdc3 {
						regulator-name = "axp803-dcdc3";
						regulator-min-microvolt = <500000>;
						regulator-max-microvolt = <1300000>;
						regulator-boot-on;
						regulator-always-on;
					};
					reg_dcdc4: dcdc4 {
						regulator-name = "axp803-dcdc4";
						regulator-min-microvolt = <500000>;
						regulator-max-microvolt = <1300000>;
						regulator-boot-on;
						regulator-always-on;
					};
					reg_dcdc5: dcdc5 {
						regulator-name = "axp803-dcdc5";
						regulator-min-microvolt = <800000>;
						regulator-max-microvolt = <1840000>;
						regulator-always-on;
					};
					reg_dcdc6: dcdc6 {
						regulator-name = "axp803-dcdc6";
						regulator-min-microvolt = <600000>;
						regulator-max-microvolt = <1520000>;
					};
					reg_dcdc7: dcdc7 {
						regulator-name = "axp803-dcdc7";
						regulator-min-microvolt = <600000>;
						regulator-max-microvolt = <1520000>;
					};
					reg_rtcldo: rtcldo {
						/* RTC_LDO is a fixed, always-on regulator */
						regulator-name = "axp803-rtcldo";
						regulator-min-microvolt = <1800000>;
						regulator-max-microvolt = <1800000>;
						regulator-boot-on;
						regulator-always-on;
					};
					reg_aldo1: aldo1 {
						regulator-name = "axp803-aldo1";
						regulator-min-microvolt = <700000>;
						regulator-max-microvolt = <3300000>;
						regulator-boot-on;
						regulator-always-on;
					};
					reg_aldo2: aldo2 {
						regulator-name = "axp803-aldo2";
						regulator-min-microvolt = <700000>;
						regulator-max-microvolt = <3300000>;
					};
					reg_aldo3: aldo3 {
						regulator-name = "axp803-aldo3";
						regulator-min-microvolt = <700000>;
						regulator-max-microvolt = <3300000>;
						regulator-always-on;
						regulator-boot-on;
					};
					reg_dldo1: dldo1 {
						regulator-name = "axp803-dldo1";
						regulator-min-microvolt = <3300000>;
						regulator-max-microvolt = <3300000>;
					};
					reg_dldo2: dldo2 {
						regulator-name = "axp803-dldo2";
						regulator-min-microvolt = <700000>;
						regulator-max-microvolt = <4200000>;
					};
					reg_dldo3: dldo3 {
						regulator-name = "axp803-dldo3";
						regulator-min-microvolt = <700000>;
						regulator-max-microvolt = <3300000>;
					};
					reg_dldo4: dldo4 {
						regulator-name = "axp803-dldo4";
						regulator-min-microvolt = <700000>;
						regulator-max-microvolt = <3300000>;
					};
					reg_eldo1: eldo1 {
						regulator-name = "axp803-eldo1";
						regulator-min-microvolt = <700000>;
						regulator-max-microvolt = <1900000>;
					};
					reg_eldo2: eldo2 {
						regulator-name = "axp803-eldo2";
						regulator-min-microvolt = <700000>;
						regulator-max-microvolt = <1900000>;
					};
					reg_eldo3: eldo3 {
						regulator-name = "axp803-eldo3";
						regulator-min-microvolt = <700000>;
						regulator-max-microvolt = <1900000>;
					};
					reg_fldo1: fldo1 {
						regulator-name = "axp803-fldo1";
						regulator-min-microvolt = <700000>;
						regulator-max-microvolt = <1450000>;
						regulator-always-on;
					};
					reg_fldo2: fldo2 {
						regulator-name = "axp803-fldo2";
						regulator-min-microvolt = <700000>;
						regulator-max-microvolt = <1450000>;
					};
					reg_ldoio0: ldoio0 {
						regulator-name = "axp803-ldoio0";
						regulator-min-microvolt = <700000>;
						regulator-max-microvolt = <3300000>;
					};
					reg_ldoio1: ldoio1 {
						regulator-name = "axp803-ldoio1";
						regulator-min-microvolt = <700000>;
						regulator-max-microvolt = <3300000>;
					};
					reg_dc1sw: dc1sw {
						regulator-name = "axp803-dc1sw";
					};
					reg_drivevbus: drivevbus {
						regulator-name = "axp803-drivevbus";
					};
				};

				virtual-dcdc1 {
					compatible = "xpower-vregulator,dcdc1";
					dcdc1-supply = <&reg_dcdc1>;
				};
				virtual-dcdc2 {
					compatible = "xpower-vregulator,dcdc2";
					dcdc2-supply = <&reg_dcdc2>;
				};
				virtual-dcdc3 {
					compatible = "xpower-vregulator,dcdc3";
					dcdc3-supply = <&reg_dcdc3>;
				};
				virtual-dcdc4 {
					compatible = "xpower-vregulator,dcdc4";
					dcdc4-supply = <&reg_dcdc4>;
				};
				virtual-dcdc5 {
					compatible = "xpower-vregulator,dcdc5";
					dcdc5-supply = <&reg_dcdc5>;
				};
				virtual-dcdc6 {
					compatible = "xpower-vregulator,dcdc6";
					dcdc6-supply = <&reg_dcdc6>;
				};
				virtual-dcdc7 {
					compatible = "xpower-vregulator,dcdc7";
					dcdc7-supply = <&reg_dcdc7>;
				};
				virtual-rtcldo {
					compatible = "xpower-vregulator,rtcldo";
					rtcldo-supply = <&reg_rtcldo>;
				};
				virtual-aldo1 {
					compatible = "xpower-vregulator,aldo1";
					aldo1-supply = <&reg_aldo1>;
				};
				virtual-aldo2 {
					compatible = "xpower-vregulator,aldo2";
					aldo2-supply = <&reg_aldo2>;
				};
				virtual-aldo3 {
					compatible = "xpower-vregulator,aldo3";
					aldo3-supply = <&reg_aldo3>;
				};
				virtual-dldo1 {
					compatible = "xpower-vregulator,dldo1";
					dldo1-supply = <&reg_dldo1>;
				};
				virtual-dldo2 {
					compatible = "xpower-vregulator,dldo2";
					dldo2-supply = <&reg_dldo2>;
				};
				virtual-dldo3 {
					compatible = "xpower-vregulator,dldo3";
					dldo3-supply = <&reg_dldo3>;
				};
				virtual-dldo4 {
					compatible = "xpower-vregulator,dldo4";
					dldo4-supply = <&reg_dldo4>;
				};
				virtual-eldo1 {
					compatible = "xpower-vregulator,eldo1";
					eldo1-supply = <&reg_eldo1>;
				};
				virtual-eldo2 {
					compatible = "xpower-vregulator,eldo2";
					eldo2-supply = <&reg_eldo2>;
				};
				virtual-eldo3 {
					compatible = "xpower-vregulator,eldo3";
					eldo3-supply = <&reg_eldo3>;
				};
				virtual-fldo1 {
					compatible = "xpower-vregulator,fldo1";
					fldo1-supply = <&reg_fldo1>;
				};
				virtual-fldo2 {
					compatible = "xpower-vregulator,fldo2";
					fldo2-supply = <&reg_fldo2>;
				};
				virtual-ldoio0 {
					compatible = "xpower-vregulator,ldoio0";
					ldoio0-supply = <&reg_ldoio0>;
				};
				virtual-ldoio1 {
					compatible = "xpower-vregulator,ldoio1";
					ldoio1-supply = <&reg_ldoio1>;
				};
				virtual-dc1sw {
					compatible = "xpower-vregulator,dc1sw";
					dc1sw-supply = <&reg_dc1sw>;
				};
				virtual-drivevbus {
					compatible = "xpower-vregulator,drivevbus";
					drivevbus-supply = <&reg_drivevbus>;
				};

				axp_gpio0: axp_gpio@0 {
					gpio-controller;
					#size-cells = <0>;
					#gpio-cells = <6>;
					status = "okay";
				};
			};
		};

		twi7: s_twi@0x07081800 {
			#address-cells = <1>;
			#size-cells = <0>;
			compatible = "allwinner,sun50i-twi";
			reg = <0x0 0x07081800 0x0 0x200>;
			interrupts = <GIC_SPI 114 IRQ_TYPE_LEVEL_HIGH>;
			clocks = <&clk_stwi1>;
			clock-frequency = <200000>;
			pinctrl-names = "default", "sleep";
			pinctrl-0 = <&s_twi1_pins_a>;
			pinctrl-1 = <&s_twi1_pins_b>;
			status = "disabled";
		};

		usbc0:usbc0@0 {
			device_type = "usbc0";
			compatible = "allwinner,sunxi-otg-manager";
			usb_port_type = <0x2>;
			usb_detect_type = <0x1>;
			usb_id_gpio = <&pio PF 0 0 0 0xffffffff 0xffffffff>;
			usb_det_vbus_gpio   = "axp_ctrl";
			usb_regulator_io = "nocare";
			usb_wakeup_suspend = <0>;
			usb_luns = <3>;
			usb_serial_unique = <0>;
			usb_serial_number = "20080411";
			rndis_wceis = <1>;
			status = "okay";
		};

		udc:udc-controller@0x05100000 {
			compatible = "allwinner,sunxi-udc";
			reg = <0x0 0x05100000 0x0 0x1000>, /*udc base*/
			      <0x0 0x00000000 0x0 0x100>, /*sram base*/
			      <0x0 0x05200000 0x0 0x1000>; /*usb1 base, for common circuit*/
			interrupts = <GIC_SPI 32 IRQ_TYPE_LEVEL_HIGH>;
			clocks = <&clk_usbphy0>, <&clk_usbotg>;
			status = "okay";
		};

		ehci0:ehci0-controller@0x05101000 {
			compatible = "allwinner,sunxi-ehci0";
			reg = <0x0 0x05101000 0x0 0xFFF>, /*hci0 base*/
			      <0x0 0x00000000 0x0 0x100>, /*sram base*/
			      <0x0 0x05100000 0x0 0x1000>, /*otg base*/
			      <0x0 0x07010250 0x0 0x10>,   /*prcm base, for usb standby*/
			      <0x0 0x03001000 0x0 0x20>,   /*ccmu base, for common circuit*/
			      <0x0 0x05200000 0x0 0x1000>; /*usb1 base, for common circuit*/
			interrupts = <GIC_SPI 30 IRQ_TYPE_LEVEL_HIGH>;
			clocks = <&clk_usbphy0>, <&clk_usbehci0>;
			hci_ctrl_no = <0>;
			drvvbus-supply = <&reg_drivevbus>;
			status = "okay";
		};

		ohci0:ohci0-controller@0x05101400 {
			compatible = "allwinner,sunxi-ohci0";
			reg = <0x0 0x05101000 0x0 0xFFF>, /*hci0 base*/
			      <0x0 0x00000000 0x0 0x100>, /*sram base*/
			      <0x0 0x05100000 0x0 0x1000>, /*otg base*/
			      <0x0 0x07010250 0x0 0x10>,   /*prcm base, for usb standby*/
			      <0x0 0x03001000 0x0 0x20>,   /*ccmu base, for common circuit*/
			      <0x0 0x05200000 0x0 0x1000>; /*usb1 base, for common circuit*/
			interrupts = <GIC_SPI 31 IRQ_TYPE_LEVEL_HIGH>;
			clocks = <&clk_usbphy0>, <&clk_usbohci0>, <&clk_usbohci0_12m>, <&clk_osc48md4>, <&clk_hosc>, <&clk_losc>;
			hci_ctrl_no = <0>;
			drvvbus-supply = <&reg_drivevbus>;
			status = "okay";
		};

		usbc1:usbc1@0 {
			device_type = "usbc1";
			usb_regulator_io = "nocare";
			usb_wakeup_suspend = <0>;
			status = "okay";
		};

		ehci1:ehci1-controller@0x05200000 {
			compatible = "allwinner,sunxi-ehci1";
			reg = <0x0 0x05200000 0x0 0xFFF>, /*hci0 base*/
			      <0x0 0x00000000 0x0 0x100>, /*sram base*/
			      <0x0 0x05100000 0x0 0x1000>, /*otg base*/
			      <0x0 0x07010250 0x0 0x10>;   /*prcm base, for usb standby*/
			interrupts = <GIC_SPI 33 IRQ_TYPE_LEVEL_HIGH>;
			clocks = <&clk_usbphy1>, <&clk_usbehci1>;
			hci_ctrl_no = <1>;
			drvvbus-supply = <&reg_usb1_vbus>;
			status = "okay";
		};

		ohci1:ohci1-controller@0x05200400 {
			compatible = "allwinner,sunxi-ohci1";
			reg = <0x0 0x05200000 0x0 0xFFF>, /*hci0 base*/
			      <0x0 0x00000000 0x0 0x100>, /*sram base*/
			      <0x0 0x05100000 0x0 0x1000>, /*otg base*/
			      <0x0 0x07010250 0x0 0x10>;   /*prcm base, for usb standby*/
			interrupts = <GIC_SPI 34 IRQ_TYPE_LEVEL_HIGH>;
			clocks = <&clk_usbphy1>, <&clk_usbohci1>, <&clk_usbohci1_12m>, <&clk_osc48md4>, <&clk_hosc>, <&clk_losc>;
			hci_ctrl_no = <1>;
			drvvbus-supply = <&reg_usb1_vbus>;
			status = "okay";
		};

		codec:codec@0x05096000 {
			compatible = "allwinner,sunxi-internal-codec";
			reg = <0x0 0x05096000 0x0 0x32c>;
			clocks = <&clk_pll_audiox4>,<&clk_codec_dac_1x>,<&clk_codec_adc_1x>,<&clk_pll_com>,<&clk_pll_comdiv5>;
			device_type = "codec";
			mic1gain 	= <0x17>;
			mic2gain 	= <0x17>;
			headphonegain	= <0x00>;
			/* adc/dac DRC/HPF func enabled */
			adcdrc_cfg 	= <0x00>;
			adchpf_cfg 	= <0x00>;
			dacdrc_cfg 	= <0x00>;
			dachpf_cfg 	= <0x00>;
			/* Volume about */
			digital_vol 	= <0x00>;
			lineout_vol 	= <0x1a>;
			dac_digital_vol = <0x1A0A0>;
			/* Pa enabled about */
			pa_level 	= <0x01>;
			pa_msleep_time 	= <0xa0>;
			gpio-spk = <&pio PF 2 1 1 1 1>;
			/* regulator about */
			avcc-supply = <&reg_aldo1>;
			cpvin-supply = <&reg_eldo1>;
			status = "okay";
		};

		cpudai:cpudai-controller@0x050906000 {
			compatible = "allwinner,sunxi-internal-cpudai";
			reg = <0x0 0x05096000 0x0 0x32c>;
			status = "okay";
		};

		sndcodec:sound@0 {
			compatible = "allwinner,sunxi-codec-machine";
			interrupts = <GIC_SPI 25 IRQ_TYPE_LEVEL_HIGH>;
			sunxi,cpudai-controller = <&cpudai>;
			sunxi,audio-codec = <&codec>;
			hp_detect_case = <0x00>;
			device_type = "sndcodec";
			status = "okay";
		};

		spdif:spdif-controller@0x05094000{
			compatible = "allwinner,sunxi-spdif";
			reg = <0x0 0x05094000 0x0 0x40>;
			clocks = <&clk_pll_audio>,<&clk_pll_audiox4>,<&clk_spdif>;
			pinctrl-names = "default","sleep";
			pinctrl-0 = <&spdif_pins_a>;
			pinctrl-1 = <&spdif_pins_b>;
			device_type = "spdif";
			status = "okay";
		};

		sndspdif:sound@1{
			compatible = "allwinner,sunxi-spdif-machine";
			sunxi,spdif-controller = <&spdif>;
			device_type = "sndspdif";
			status = "okay";
		};

		dmic:dmic-controller@0x05095000{
			compatible = "allwinner,sunxi-dmic";
			reg = <0x0 0x05095000 0x0 0x50>;
			clocks = <&clk_pll_audio>,<&clk_pll_audiox4>,<&clk_dmic>;
			pinctrl-names = "default","sleep";
			pinctrl-0 = <&dmic_pins_a>;
			pinctrl-1 = <&dmic_pins_b>;
			device_type = "dmic";
			status = "okay";
		};

		snddmic:sound@2{
			compatible = "allwinner,sunxi-dmic-machine";
			sunxi,dmic-controller = <&dmic>;
			device_type = "snddmic";
			status = "okay";
		};

		daudio0:daudio@0x05090000 {
			compatible = "allwinner,sunxi-daudio";
			reg = <0x0 0x05090000 0x0 0x7c>;
			clocks = <&clk_pll_audiox4>,<&clk_i2s0>;
			pinctrl-names = "default", "sleep";
			pinctrl-0 = <&daudio0_pins_a>;
			pinctrl-1 = <&daudio0_pins_b>;
			device_type = "daudio0";
			tdm_num = <0x00>;
			mclk_div 	= <0x01>;
			frametype 	= <0x00>;
			tdm_config 	= <0x01>;
			sign_extend 	= <0x00>;
			tx_data_mode 	= <0x00>;
			rx_data_mode 	= <0x00>;
			msb_lsb_first 	= <0x00>;
			pcm_lrck_period = <0x80>;
			slot_width_select = <0x20>;
			status = "okay";
		};

		snddaudio0:sound@3{
			compatible = "allwinner,sunxi-daudio0-machine";
			sunxi,daudio-controller = <&daudio0>;
			device_type = "snddaudio0";
			sunxi,snddaudio-codec = "ac107.1-0036";
			sunxi,snddaudio-codec-dai = "ac107-pcm0";
			audio_format 	= <0x01>;
			daudio_master 	= <0x04>;
			signal_inversion  = <0x01>;
			status = "okay";
		};

		daudio1:daudio@0x05091000 {
			compatible = "allwinner,sunxi-daudio";
			reg = <0x0 0x05091000 0x0 0x7c>;
			clocks = <&clk_pll_audiox4>,<&clk_i2s1>;
			pinctrl-names = "default", "sleep";
			pinctrl-0 = <&daudio1_pins_a>;
			pinctrl-1 = <&daudio1_pins_b>;
			device_type = "daudio1";
			tdm_num = <0x01>;
			mclk_div 	= <0x01>;
			frametype 	= <0x00>;
			tdm_config 	= <0x01>;
			sign_extend 	= <0x00>;
			tx_data_mode 	= <0x00>;
			rx_data_mode 	= <0x00>;
			msb_lsb_first 	= <0x00>;
			pcm_lrck_period = <0x20>;
			slot_width_select = <0x20>;
			status = "disabled";
		};

		snddaudio1:sound@4{
			compatible = "allwinner,sunxi-daudio1-machine";
			sunxi,daudio-controller = <&daudio1>;
			device_type = "snddaudio1";
			audio_format 	= <0x01>;
			daudio_master 	= <0x04>;
			signal_inversion  = <0x01>;
			status = "disabled";
		};

		daudio2:daudio@0x05092000 {
			compatible = "allwinner,sunxi-daudio";
			reg = <0x0 0x05092000 0x0 0x7c>;
			clocks = <&clk_pll_audiox4>,<&clk_i2s2>;
			pinctrl-names = "default", "sleep";
			pinctrl-0 = <&daudio2_pins_a>;
			pinctrl-1 = <&daudio2_pins_b>;
			device_type = "daudio2";
			tdm_num = <0x02>;
			mclk_div 	= <0x01>;
			frametype 	= <0x00>;
			tdm_config 	= <0x01>;
			sign_extend 	= <0x00>;
			tx_data_mode 	= <0x00>;
			rx_data_mode 	= <0x00>;
			msb_lsb_first 	= <0x00>;
			pcm_lrck_period = <0x20>;
			slot_width_select = <0x20>;
			status = "disabled";
		};

		snddaudio2:sound@5{
			compatible = "allwinner,sunxi-daudio2-machine";
			sunxi,daudio-controller = <&daudio2>;
			device_type = "snddaudio2";
			audio_format 	= <0x01>;
			daudio_master 	= <0x04>;
			signal_inversion  = <0x01>;
			status = "disabled";
		};

		daudio3:daudio@0x05093000 {
			compatible = "allwinner,sunxi-daudio";
			reg = <0x0 0x05093000 0x0 0x7c>;
			clocks = <&clk_pll_audiox4>,<&clk_i2s3>;
			pinctrl-names = "default", "sleep";
			pinctrl-0 = <&daudio3_pins_a>;
			pinctrl-1 = <&daudio3_pins_b>;
			device_type = "daudio3";
			tdm_num = <0x03>;
			mclk_div 	= <0x01>;
			frametype 	= <0x00>;
			tdm_config 	= <0x01>;
			sign_extend 	= <0x00>;
			tx_data_mode 	= <0x00>;
			rx_data_mode 	= <0x00>;
			msb_lsb_first 	= <0x00>;
			pcm_lrck_period = <0x20>;
			slot_width_select = <0x20>;
			status = "disabled";
		};

		snddaudio3:sound@6{
			compatible = "allwinner,sunxi-daudio3-machine";
			sunxi,daudio-controller = <&daudio3>;
			device_type = "snddaudio3";
			audio_format 	= <0x01>;
			daudio_master 	= <0x04>;
			signal_inversion  = <0x01>;
			status = "disabled";
		};

		spi0: spi@05010000 {
			#address-cells = <1>;
			#size-cells = <0>;
			compatible = "allwinner,sun50i-spi";
			device_type = "spi0";
			reg = <0x0 0x05010000 0x0 0x1000>;
			interrupts = <GIC_SPI 13 IRQ_TYPE_LEVEL_HIGH>;
			clocks = <&clk_pll_periph0>, <&clk_spi0>;
			clock-frequency = <100000000>;
			pinctrl-names = "default", "sleep";
			pinctrl-0 = <&spi0_pins_a &spi0_pins_b>;
			pinctrl-1 = <&spi0_pins_c>;
			spi0_cs_number = <1>;
			spi0_cs_bitmap = <1>;
			spi_slave_mode = <0>;
			status = "disabled";
			spi_board0 {
				device_type = "spi_board0";
				compatible = "rohm,dh2228fv";
				spi-max-frequency = <0x5f5e100>;
				reg = <0x0>;
				spi-rx-bus-width = <0x1>;
				spi-tx-bus-width = <0x1>;
				status = "disabled";
			};
		};

		spi1: spi@05011000 {
			#address-cells = <1>;
			#size-cells = <0>;
			compatible = "allwinner,sun50i-spi";
			device_type = "spi1";
			reg = <0x0 0x05011000 0x0 0x1000>;
			interrupts = <GIC_SPI 14 IRQ_TYPE_LEVEL_HIGH>;
			clocks = <&clk_pll_periph0>, <&clk_spi1>;
			clock-frequency = <100000000>;
			pinctrl-names = "default", "sleep";
			pinctrl-0 = <&spi1_pins_a &spi1_pins_b>;
			pinctrl-1 = <&spi1_pins_c>;
			spi1_cs_number = <1>;
			spi1_cs_bitmap = <1>;
			spi_slave_mode = <0>;
			status = "disabled";
			spi_board1 {
				device_type = "spi_board1";
				compatible = "rohm,dh2228fv";
				spi-max-frequency = <0x5f5e100>;
				reg = <0x0>;
				spi-rx-bus-width = <0x1>;
				spi-tx-bus-width = <0x1>;
				status = "disabled";
			};
		};

		spi2: spi@05012000 {
			#address-cells = <1>;
			#size-cells = <0>;
			compatible = "allwinner,sun50i-spi";
			device_type = "spi2";
			reg = <0x0 0x05012000 0x0 0x1000>;
			interrupts = <GIC_SPI 15 IRQ_TYPE_LEVEL_HIGH>;
			clocks = <&clk_pll_periph0>, <&clk_spi2>;
			clock-frequency = <100000000>;
			pinctrl-names = "default", "sleep";
			pinctrl-0 = <&spi2_pins_a &spi2_pins_b>;
			pinctrl-1 = <&spi2_pins_c>;
			spi2_cs_number = <1>;
			spi2_cs_bitmap = <1>;
			spi_slave_mode = <0>;
			status = "disabled";
			spi_board1 {
				device_type = "spi_board2";
				compatible = "rohm,dh2228fv";
				spi-max-frequency = <0x5f5e100>;
				reg = <0x0>;
				spi-rx-bus-width = <0x1>;
				spi-tx-bus-width = <0x1>;
				status = "disabled";
			};
		};

		ledc: ledc@0x05018000 {
			#address-cells = <1>;
			#size-cells = <0>;
			compatible = "allwinner,sunxi-leds";
			reg = <0x0 0x05018000 0x0 0x100>;
			interrupts = <GIC_SPI 35 IRQ_TYPE_LEVEL_HIGH>;
			interrupt-names = "ledcirq";
			clocks = <&clk_ledc>, <&clk_cpuapb>;
			clock-names = "clk_ledc", "clk_cpuapb";
			pinctrl-names = "default", "sleep";
			pinctrl-0 = <&ledc_pins_a>;
			pinctrl-1 = <&ledc_pins_b>;
			led_count         = <34>;
			output_mode       = "GRB";
			reset_ns          = <84>;
			t1h_ns            = <800>;
			t1l_ns            = <450>;
			t0h_ns            = <400>;
			t0l_ns            = <850>;
			wait_time0_ns     = <84>;
			wait_time1_ns     = <84>;
			wait_data_time_ns = <600000>;
			status		  = "okay";
		};

		pcie: pcie@0x05400000 {
			#address-cells = <3>;
			#size-cells = <2>;
			compatible = "allwinner,sun50i-pcie";
			reg = <0 0x05400000 0 0x2000>,
			      <0 0x05410000 0 0x10000>;
			reg-names = "dbi", "config";
			device_type = "pci";
			ranges = <0x00000800 0 0x05410000 0 0x05410000 0 0x00010000 /* configuration space */
				  0x81000000 0 0          0 0x05e00000 0 0x00010000 /* downstream I/O */
				  0x82000000 0 0x05500000 0 0x05500000 0 0x00800000>; /* non-prefetchable memory */
			num-lanes = <1>;
			interrupts = <GIC_SPI 127 IRQ_TYPE_LEVEL_HIGH>,
				     <GIC_SPI 126 IRQ_TYPE_LEVEL_HIGH>;
			interrupt-names = "msi";
			/*clocks = <&clk_pcieref>,
				<&clk_pciemaxi>,
				<&clk_pcieaux>,
				<&clk_pcie_bus>,
				<&clk_pcie_power>,
				<&clk_pcie_rst>;*/
			#interrupt-cells = <1>;
			interrupt-map-mask = <0 0 0 0>;
			interrupt-map = <0 0 0 1 &gic GIC_SPI 127 IRQ_TYPE_LEVEL_HIGH>;
			status = "okay";
		};

		sdc2: sdmmc@04022000 {
			compatible = "allwinner,sunxi-mmc-v4p6x";
			device_type = "sdc2";
			reg = <0x0 0x04022000 0x0 0x1000>;
			interrupts = <GIC_SPI 41 IRQ_TYPE_LEVEL_HIGH>;
			clocks = <&clk_hosc>,
				 <&clk_pll_periph1x2>,
				 <&clk_sdmmc2_mod>,
				 <&clk_sdmmc2_bus>,
				 <&clk_sdmmc2_rst>;
			clock-names = "osc24m","pll_periph","mmc","ahb","rst";
			pinctrl-names = "default","sleep";
			pinctrl-0 = <&sdc2_pins_a &sdc2_pins_c>;
			pinctrl-1 = <&sdc2_pins_b>;
			bus-width = <8>;
			cap-mmc-highspeed;
			cap-cmd23;
			mmc-cache-ctrl;
			non-removable;
			/*max-frequency = <200000000>;*/
			max-frequency = <100000000>;
			cap-erase;
			mmc-high-capacity-erase-size;
			no-sdio;
			no-sd;
			/*-- speed mode --*/
			/*sm0: DS26_SDR12*/
			/*sm1: HSSDR52_SDR25*/
			/*sm2: HSDDR52_DDR50*/
			/*sm3: HS200_SDR104*/
			/*sm4: HS400*/
			/*-- frequency point --*/
			/*f0: CLK_400K*/
			/*f1: CLK_25M*/
			/*f2: CLK_50M*/
			/*f3: CLK_100M*/
			/*f4: CLK_150M*/
			/*f5: CLK_200M*/

			sdc_tm4_sm0_freq0 = <0>;
			sdc_tm4_sm0_freq1 = <0>;
			sdc_tm4_sm1_freq0 = <0x00000000>;
			sdc_tm4_sm1_freq1 = <0>;
			sdc_tm4_sm2_freq0 = <0x00000000>;
			sdc_tm4_sm2_freq1 = <0>;
			sdc_tm4_sm3_freq0 = <0x05000000>;
			sdc_tm4_sm3_freq1 = <0x00000005>;
			sdc_tm4_sm4_freq0 = <0x00050000>;
			sdc_tm4_sm4_freq1 = <0x00000004>;
			mmc-ddr-1_8v;
			mmc-hs200-1_8v;
			mmc-hs400-1_8v;
			sunxi-power-save-mode;
			sunxi-dis-signal-vol-sw;
			vmmc-supply = <&reg_dcdc1>;
			vqmmc-supply = <&reg_aldo1>;


			/*vmmc-supply = <&reg_3p3v>;*/
			/*vqmc-supply = <&reg_3p3v>;*/
			/*vdmc-supply = <&reg_3p3v>;*/
			/*vmmc = "vcc-card";*/
			/*vqmc = "";*/
			/*vdmc = "";*/
			/*sunxi-power-save-mode;*/
			status = "okay";
		};

		sdc0: sdmmc@04020000 {
			compatible = "allwinner,sunxi-mmc-v5p3x";
			device_type = "sdc0";
			reg = <0x0 0x04020000 0x0 0x1000>;
			interrupts = <GIC_SPI 39 IRQ_TYPE_LEVEL_HIGH>;
			clocks = <&clk_hosc>,
				 <&clk_pll_periph1x2>,
				 <&clk_sdmmc0_mod>,
				 <&clk_sdmmc0_bus>,
				 <&clk_sdmmc0_rst>;
			clock-names = "osc24m","pll_periph","mmc","ahb","rst";
			pinctrl-names = "default","sleep","uart_jtag";
			pinctrl-0 = <&sdc0_pins_a>;
			pinctrl-1 = <&sdc0_pins_b>;
			pinctrl-2 = <&sdc0_pins_c>;
			max-frequency = <150000000>;
			bus-width = <4>;
			/*non-removable;*/
			/*broken-cd;*/
			/*cd-inverted*/
			/*cd-gpios = <&pio PF 6 0 1 2 0>;*/
			/* vmmc-supply = <&reg_3p3v>;*/
			/* vqmc-supply = <&reg_3p3v>;*/
			/* vdmc-supply = <&reg_3p3v>;*/
			/*vmmc = "vcc-card";*/
			/*vqmc = "";*/
			/*vdmc = "";*/
			cap-sd-highspeed;
			cap-wait-while-busy;
			no-sdio;
			no-mmc;
			/*sd-uhs-sdr50;*/
			/*sd-uhs-ddr50;*/
			/*cap-sdio-irq;*/
			/*keep-power-in-suspend;*/
			/*ignore-pm-notify;*/
			/*sunxi-power-save-mode;*/
			/*sunxi-dly-400k = <1 0 0 0>; */
			/*sunxi-dly-26M  = <1 0 0 0>;*/
			/*sunxi-dly-52M  = <1 0 0 0>;*/
			/*sunxi-dly-52M-ddr4  = <1 0 0 0>;*/
			/*sunxi-dly-52M-ddr8  = <1 0 0 0>;*/
			/*sunxi-dly-104M  = <1 0 0 0>;*/
			/*sunxi-dly-208M  = <1 0 0 0>;*/
			/*sunxi-dly-104M-ddr  = <1 0 0 0>;*/
			/*sunxi-dly-208M-ddr  = <1 0 0 0>;*/
			cd-gpios = <&pio PF 6 6 1 3 0xffffffff>;
			cd-used-24M;
			sd-uhs-sdr50;
			sd-uhs-ddr50;
			sd-uhs-sdr104;
			vmmc-supply = <&reg_dcdc1>;
			vqmmc33sw-supply = <&reg_dcdc1>;
			vdmmc33sw-supply = <&reg_dcdc1>;
			vqmmc18sw-supply = <&reg_eldo1>;
			vdmmc18sw-supply = <&reg_eldo1>;

			status = "disabled";
		};

		sdc1: sdmmc@04021000 {
			compatible = "allwinner,sunxi-mmc-v5p3x";
			device_type = "sdc1";
			reg = <0x0 0x04021000 0x0 0x1000>;
			interrupts = <GIC_SPI 40 IRQ_TYPE_LEVEL_HIGH>;
			clocks = <&clk_hosc>,
				 <&clk_pll_periph1x2>,
				 <&clk_sdmmc1_mod>,
				 <&clk_sdmmc1_bus>,
				 <&clk_sdmmc1_rst>;
			clock-names = "osc24m","pll_periph","mmc","ahb","rst";
			pinctrl-names = "default","sleep";
			pinctrl-0 = <&sdc1_pins_a>;
			pinctrl-1 = <&sdc1_pins_b>;
			max-frequency = <50000000>;
			bus-width = <4>;
			/*broken-cd;*/
			/*cd-inverted*/
			/*cd-gpios = <&pio PG 6 6 1 2 0>;*/
			/* vmmc-supply = <&reg_3p3v>;*/
			/* vqmc-supply = <&reg_3p3v>;*/
			/* vdmc-supply = <&reg_3p3v>;*/
			/*vmmc = "vcc-card";*/
			/*vqmc = "";*/
			/*vdmc = "";*/
			cap-sd-highspeed;
			no-mmc;
			/*sd-uhs-sdr50;*/
			/*sd-uhs-ddr50;*/
			/*sd-uhs-sdr104;*/
			/*cap-sdio-irq;*/
			keep-power-in-suspend;
			/*ignore-pm-notify;*/
			/*sunxi-power-save-mode;*/
			/*sunxi-dly-400k = <1 0 0 0 0>; */
			/*sunxi-dly-26M  = <1 0 0 0 0>;*/
			/*sunxi-dly-52M  = <1 0 0 0 0>;*/
			sunxi-dly-52M-ddr4  = <1 0 0 0 2>;
			/*sunxi-dly-52M-ddr8  = <1 0 0 0 0>;*/
			sunxi-dly-104M  = <1 0 0 0 1>;
			/*sunxi-dly-208M  = <1 1 0 0 0>;*/
			sunxi-dly-208M  = <1 0 0 0 1>;
			/*sunxi-dly-104M-ddr  = <1 0 0 0 0>;*/
			/*sunxi-dly-208M-ddr  = <1 0 0 0 0>;*/
			no-sd;
			cap-sdio-irq;
			ignore-pm-notify;

			status = "okay";
		};

		sdc3: sdmmc@04023000 {
			compatible = "allwinner,sunxi-mmc-v5p3x";
			device_type = "sdc3";
			reg = <0x0 0x04023000 0x0 0x1000>;
			interrupts = <GIC_SPI 42 IRQ_TYPE_LEVEL_HIGH>;
			/*the system has not configured sdmmc3 clk*/
			/*clocks = <&clk_hosc>,*/
			/*	 <&clk_pll_periph1x2>,*/
			/*	 <&clk_sdmmc3_mod>,*/
			/*	 <&clk_sdmmc3_bus>,*/
			/*	 <&clk_sdmmc3_rst>;*/
			/*clock-names = "osc24m","pll_periph","mmc","ahb","rst";*/
			pinctrl-names = "default","sleep";
			pinctrl-0 = <&sdc3_pins_a>;
			pinctrl-1 = <&sdc3_pins_b>;
			max-frequency = <50000000>;
			bus-width = <4>;
			cap-sd-highspeed;
			no-sdio;
			no-mmc;
			/*broken-cd;*/
			/*cd-inverted*/
			/*cd-gpios = <&pio PG 6 6 1 2 0>;*/
			/* vmmc-supply = <&reg_3p3v>;*/
			/* vqmc-supply = <&reg_3p3v>;*/
			/* vdmc-supply = <&reg_3p3v>;*/
			/*vmmc = "vcc-card";*/
			/*vqmc = "";*/
			/*vdmc = "";*/
			/*sd-uhs-sdr50;*/
			/*sd-uhs-ddr50;*/
			/*sd-uhs-sdr104;*/
			/*cap-sdio-irq;*/
			/*keep-power-in-suspend;*/
			/*ignore-pm-notify;*/
			/*sunxi-power-save-mode;*/
			/*sunxi-dly-400k = <1 0 0 0 0>; */
			/*sunxi-dly-26M  = <1 0 0 0 0>;*/
			/*sunxi-dly-52M  = <1 0 0 0 0>;*/
			/*sunxi-dly-52M-ddr8  = <1 0 0 0 0>;*/
			/*sunxi-dly-208M  = <1 1 0 0 0>;*/
			/*sunxi-dly-104M-ddr  = <1 0 0 0 0>;*/
			/*sunxi-dly-208M-ddr  = <1 0 0 0 0>;*/

			status = "disabled";
			/*status = "okay";*/
		};

		disp1: disp1@1 {
			compatible = "allwinner,sunxi-disp";
			iommus = <&mmu_aw 1 1>;
		};

		disp: disp@06000000 {
			compatible = "allwinner,sunxi-disp";
			reg = <0x0 0x06000000 0x0 0x3fffff>,/*de0*/
			      <0x0 0x06800000 0x0 0x3fffff>,/*de1*/
			      <0x0 0x06510000 0x0 0xfff>,/*tcon-top0*/
			      <0x0 0x06d10000 0x0 0xfff>,/*tcon-top1*/
			      <0x0 0x06511000 0x0 0xfff>,/*tcon-lcd0*/
			      <0x0 0x06d11000 0x0 0xfff>,/*tcon-lcd1*/
			      <0x0 0x06504000 0x0 0x1fff>;/*dsi0*/
			interrupts = <GIC_SPI 69 IRQ_TYPE_LEVEL_HIGH>,
				     <GIC_SPI 70 IRQ_TYPE_LEVEL_HIGH>,
				     <GIC_SPI 68 IRQ_TYPE_LEVEL_HIGH>;
			clocks = <&clk_de0>,
				 <&clk_de1>,
				 <&clk_display_top>,
				 <&clk_dpss_top0>,
				 <&clk_dpss_top1>,
				 <&clk_tcon_lcd0>,
				 <&clk_tcon_lcd1>,
				 <&clk_lvds>,
				 <&clk_lvds1>,
				 <&clk_mipi_host>;
			boot_disp = <0>;
			boot_disp1 = <0>;
			boot_disp2 = <0>;
			fb_base = <0>;
			iommus = <&mmu_aw 0 0>;
			disp_init_enable         = <0>;
			disp_mode                = <0>;

			screen0_output_type      = <1>;
			screen0_output_mode      = <4>;

			screen1_output_type      = <3>;
			screen1_output_mode      = <10>;

			screen1_output_format    = <0>;
			screen1_output_bits      = <0>;
			screen1_output_eotf      = <4>;
			screen1_output_cs        = <257>;
			screen1_output_dvi_hdmi  = <2>;
			screen1_output_range     = <2>;
			screen1_output_scan      = <0>;
			screen1_output_aspect_ratio = <8>;

			dev0_output_type         = <1>;
			dev0_output_mode         = <4>;
			dev0_screen_id           = <0>;
			dev0_do_hpd              = <0>;

			dev1_output_type         = <4>;
			dev1_output_mode         = <10>;
			dev1_screen_id           = <1>;
			dev1_do_hpd              = <1>;

			def_output_dev           = <0>;
			hdmi_mode_check          = <1>;

			fb0_format               = <0>;
			fb0_width                = <800>;
			fb0_height               = <1280>;

			fb1_format               = <0>;
			fb1_width                = <0>;
			fb1_height               = <0>;
			chn_cfg_mode             = <1>;

			disp_para_zone           = <1>;
			/*VCC-LCD*/
			dc1sw-supply = <&reg_dc1sw>;
			/*VCC-DSI*/
			eldo3-supply = <&reg_eldo3>;
			/*VCC-PD*/
			dcdc1-supply = <&reg_dcdc1>;

			status = "okay";
		};

		eink: eink@06400000 {
			compatible = "allwinner,sunxi-eink";
			pinctrl-names = "active","sleep";
			reg = <0x0 0x06400000 0x0 0x01ffff>,/* eink */
			      <0x0 0x06000000 0x0 0x3fffff>;/* de */
			interrupts = <GIC_SPI 90 IRQ_TYPE_LEVEL_HIGH>, /* eink */
				     <GIC_SPI 88 IRQ_TYPE_LEVEL_HIGH>; /* de */
			clocks = <&clk_de0>,
				 <&clk_ee>,
				 <&clk_panel>;
			iommus = <&mmu_aw 6 1>;
			eink_panel_name     = "default_eink";
			eink_scan_mode      = <0>;
			eink_width          = <1024>;
			eink_height         = <758>;
			eink_bits           = <5>;
			eink_data_len       = <8>;
			eink_lsl            = <6>;
			eink_lbl            = <6>;
			eink_lel            = <38>;
			eink_fsl            = <2>;
			eink_fbl            = <4>;
			eink_fel            = <5>;
			eink_lgonl          = <262>;
			eink_gdck_sta       = <4>;
			eink_gdoe_start_line= <2>;
			eink_fresh_hz       = <85>;
			eink_gray_level     = <16>;
			eink_wav_path       = "/system/default_8_5.awf";
			vcom_path           = "/system/vcom.bin";
			/*VCC-LCD*/
			dc1sw-supply	    = <&reg_dc1sw>;
			/*VCC-PD*/
			dcdc1-supply	    = <&reg_dcdc1>;
			eink_pin_power	    = "dcdc1";
			eink_power	    = "dc1sw";
			pinctrl-0	    = <&eink_pins_a>;
			pinctrl-1	    = <&eink_pins_b>;
			status = "okay";
		};

		tps65185: tps65185@68 {
			compatible = "allwinner, tps65185";
			pinctrl-names = "active","sleep";
			tps65185_used             = <0>;
			tps65185_name             = "tps65185";
			tps65185_twi_id           = <0>;
			tps65185_twi_addr         = <0x68>;
			tps65185_wakeup           = <&pio PH 13 1 1 3 1>;
			tps65185_vcom             = <&pio PH 12 1 1 3 1>;
			tps65185_powerup          = <&pio PD 23 1 1 3 0>;
			dc1sw-supply		  = <&reg_dc1sw>;
			tps65185_ldo		  = "dc1sw";
			status = "okay";
		};

		tps65185_slave: tps65185_slave@68{
			compatible = "allwinner, tps65185_slave";
			pinctrl-names = "active","sleep";
			tps65185_used             = <0>;
			tps65185_name             = "tps65185_slave";
			tps65185_twi_id           = <1>;
			tps65185_twi_addr         = <0x68>;
			status = "okay";
		};

		lcd0: lcd0@01c0c000 {
			compatible = "allwinner,sunxi-lcd0";
			pinctrl-names = "active","sleep";
			lcd_used            = <0>;

			lcd_driver_name     = "he0801a068";
			lcd_backlight       = <50>;
			lcd_if              = <4>;

			lcd_x               = <800>;
			lcd_y               = <1280>;
			lcd_width           = <52>;
			lcd_height          = <52>;
			lcd_dclk_freq       = <78>;

			lcd_pwm_used        = <1>;
			lcd_pwm_ch          = <0>;
			lcd_pwm_freq        = <50000>;
			lcd_pwm_pol         = <0>;
			lcd_pwm_max_limit   = <255>;


			lcd_hbp             = <149>;
			lcd_ht              = <978>;
			lcd_hspw            = <16>;
			lcd_vbp             = <7>;
			lcd_vt              = <1329>;
			lcd_vspw            = <5>;

			lcd_dsi_lane        = <4>;
			lcd_lvds_if         = <0>;
			lcd_lvds_colordepth = <0>;
			lcd_lvds_mode       = <0>;
			lcd_frm             = <0>;
			lcd_hv_clk_phase    = <0>;
			lcd_hv_sync_polarity= <0>;
			lcd_gamma_en        = <0>;
			lcd_bright_curve_en = <0>;
			lcd_cmap_en         = <0>;
			lcd_fsync_en        = <0>;
			lcd_fsync_act_time  = <1000>;
			lcd_fsync_dis_time  = <1000>;
			lcd_fsync_pol       = <0>;

			deu_mode            = <0>;
			lcdgamma4iep        = <22>;
			smart_color         = <90>;

			lcd_pin_power = "dcdc1";
			lcd_pin_power1 = "eldo3";
			lcd_bl_en = <&pio PH 12 1 0 3 1>;

			lcd_power = "dc1sw";
			lcd_gpio_0 = <&pio PD 22 1 0 3 1>;
			pinctrl-0 = <&dsi4lane_pins_a>;
			pinctrl-1 = <&dsi4lane_pins_b>;

			status = "disabled";
		};

		lcd1: lcd1@01c0c001 {
			compatible = "allwinner,sunxi-lcd1";
			pinctrl-names = "active","sleep";

			status = "okay";
		};

		g2d: g2d@06480000 {
			compatible = "allwinner,sunxi-g2d";
			reg = <0x0 0x06480000 0x0 0x3ffff>;
			interrupts = <GIC_SPI 91 IRQ_TYPE_LEVEL_HIGH>;
			clocks = <&clk_g2d>;
			iommus = <&mmu_aw 5 1>;
			status = "okay";
		};

		pwm: pwm@0300a000 {
			compatible = "allwinner,sunxi-pwm";
			reg = <0x0 0x0300a000 0x0 0x3ff>;
			clocks = <&clk_pwm>;
			pwm-number = <16>;
			pwm-base = <0x0>;
			pwms = <&pwm0>, <&pwm1>, <&pwm2>, <&pwm3>, <&pwm4>,
				<&pwm5>, <&pwm6>, <&pwm7>, <&pwm8>, <&pwm9>,
				<&pwm10>, <&pwm11>, <&pwm12>, <&pwm13>,
				<&pwm14>, <&pwm15>;
		};

		pwm0: pwm0@0300a000 {
			compatible = "allwinner,sunxi-pwm0";
			pinctrl-names = "active", "sleep";
			reg_base = <0x0300a000>;
			pinctrl-0 = <&pwm0_pin_a>;
			pinctrl-1 = <&pwm0_pin_b>;
		};

		pwm1: pwm1@0300a000 {
			compatible = "allwinner,sunxi-pwm1";
			pinctrl-names = "active", "sleep";
			reg_base = <0x0300a000>;
			pinctrl-0 = <&pwm1_pin_a>;
			pinctrl-1 = <&pwm1_pin_b>;
		};

		pwm2: pwm2@0300a000 {
			compatible = "allwinner,sunxi-pwm2";
			pinctrl-names = "active", "sleep";
			reg_base = <0x0300a000>;
		};

		pwm3: pwm3@0300a000 {
			compatible = "allwinner,sunxi-pwm3";
			pinctrl-names = "active", "sleep";
			reg_base = <0x0300a000>;
		};

		pwm4: pwm4@0300a000 {
			compatible = "allwinner,sunxi-pwm4";
			pinctrl-names = "active", "sleep";
			reg_base = <0x0300a000>;
		};

		pwm5: pwm5@0300a000 {
			compatible = "allwinner,sunxi-pwm5";
			pinctrl-names = "active", "sleep";
			reg_base = <0x0300a000>;
		};

		pwm6: pwm6@0300a000 {
			compatible = "allwinner,sunxi-pwm6";
			pinctrl-names = "active", "sleep";
			reg_base = <0x0300a000>;
		};

		pwm7: pwm7@0300a000 {
			compatible = "allwinner,sunxi-pwm7";
			pinctrl-names = "active", "sleep";
			reg_base = <0x0300a000>;
		};

		pwm8: pwm8@0300a000 {
			compatible = "allwinner,sunxi-pwm8";
			pinctrl-names = "active", "sleep";
			reg_base = <0x0300a000>;
		};

		pwm9: pwm9@0300a000 {
			compatible = "allwinner,sunxi-pwm9";
			pinctrl-names = "active", "sleep";
			reg_base = <0x0300a000>;
		};

		pwm10: pwm10@0300a000 {
			compatible = "allwinner,sunxi-pwm10";
			pinctrl-names = "active", "sleep";
			reg_base = <0x0300a000>;
		};

		pwm11: pwm11@0300a000 {
			compatible = "allwinner,sunxi-pwm11";
			pinctrl-names = "active", "sleep";
			reg_base = <0x0300a000>;
		};

		pwm12: pwm12@0300a000 {
			compatible = "allwinner,sunxi-pwm12";
			pinctrl-names = "active", "sleep";
			reg_base = <0x0300a000>;
		};

		pwm13: pwm13@0300a000 {
			compatible = "allwinner,sunxi-pwm13";
			pinctrl-names = "active", "sleep";
			reg_base = <0x0300a000>;
		};

		pwm14: pwm14@0300a000 {
			compatible = "allwinner,sunxi-pwm14";
			pinctrl-names = "active", "sleep";
			reg_base = <0x0300a000>;
		};

		pwm15: pwm15@0300a000 {
			compatible = "allwinner,sunxi-pwm15";
			pinctrl-names = "active", "sleep";
			reg_base = <0x0300a000>;
		};

		boot_disp: boot_disp {
			compatible = "allwinner,boot_disp";
		};

		ac200: ac200 {
			compatible = "allwinner,sunxi-ac200";
			clocks = <&clk_tcon_lcd0>;
			pinctrl-names = "active","sleep", "ccir_clk_active",
			"ccir_clk_sleep";
			pinctrl-2 = <&ccir_clk_pin_a>;
			pinctrl-3 = <&ccir_clk_pin_b>;
			status = "okay";
		};

		vind0:vind@0 {
			compatible = "allwinner,sunxi-vin-media", "simple-bus";
			#address-cells = <2>;
			#size-cells = <2>;
			ranges;
			device_id = <0>;
			vind0_clk = <336000000>;
			vind0_isp = <327000000>;
			reg = <0x0 0x02000800 0x0 0x200>,
				<0x0 0x02000000 0x0 0x800>,
				<0x0 0x0200A000 0x0 0x100>;
			clocks = <&clk_csi_top>, <&clk_pll_video2x2>,
				 <&clk_csi_master0>, <&clk_hosc>, <&clk_pll_video2x2>,
				 <&clk_csi_master1>, <&clk_hosc>, <&clk_pll_video2x2>,
				 <&clk_csi_isp>, <&clk_pll_video3x2>;
			pinctrl-names = "mclk0-default","mclk0-sleep","mclk1-default","mclk1-sleep";
			pinctrl-0 = <&csi_mclk0_pins_a>;
			pinctrl-1 = <&csi_mclk0_pins_b>;
			pinctrl-2 = <&csi_mclk1_pins_a>;
			pinctrl-3 = <&csi_mclk1_pins_b>;
			status = "okay";

			csi0:csi@0 {
				device_type = "csi0";
				compatible = "allwinner,sunxi-csi";
				reg = <0x0 0x02001000 0x0 0x1000>;
				interrupts = <GIC_SPI 75 IRQ_TYPE_LEVEL_HIGH>;
				device_id = <0>;
				iommus = <&mmu_aw 3 1>;
				status = "okay";
			};
			csi1:csi@1 {
				device_type = "csi1";
				compatible = "allwinner,sunxi-csi";
				reg = <0x0 0x02002000 0x0 0x1000>;
				interrupts = <GIC_SPI 76 IRQ_TYPE_LEVEL_HIGH>;
				device_id = <1>;
				iommus = <&mmu_aw 3 1>;
				status = "okay";
			};
			mipi0:mipi@0 {
				compatible = "allwinner,sunxi-mipi";
				reg = <0x0 0x0200A100 0x0 0x100>,
					<0x0 0x0200B000 0x0 0x400>;
				interrupts = <GIC_SPI 80 IRQ_TYPE_LEVEL_HIGH>;
				device_id = <0>;
				status = "okay";
			};
			mipi1:mipi@1 {
				compatible = "allwinner,sunxi-mipi";
				reg = <0x0 0x0200A200 0x0 0x100>,
					<0x0 0x0200B400 0x0 0x400>;
				device_id = <1>;
				status = "okay";
			};
			tdm0:tdm@0 {
				compatible = "allwinner,sunxi-tdm";
				reg = <0x0 0x02108000 0x0 0x180>;
				interrupts = <GIC_SPI 79 IRQ_TYPE_LEVEL_HIGH>;
				device_id = <0>;
				iommus = <&mmu_aw 4 1>;
				status = "okay";
			};
			isp0:isp@0 {
				compatible = "allwinner,sunxi-isp";
				reg = <0x0 0x02100000 0x0 0x2000>;
				interrupts = <GIC_SPI 77 IRQ_TYPE_LEVEL_HIGH>;
				device_id = <0>;
				iommus = <&mmu_aw 4 1>;
				status = "okay";
			};
			isp1:isp@1 {
				compatible = "allwinner,sunxi-isp";
				reg = <0x0 0x02102000 0x0 0x2000>;
				interrupts = <GIC_SPI 78 IRQ_TYPE_LEVEL_HIGH>;
				device_id = <1>;
				iommus = <&mmu_aw 4 1>;
				status = "okay";
			};
			scaler0:scaler@0 {
				compatible = "allwinner,sunxi-scaler";
				reg = <0x0 0x02110000 0x0 0x400>;
				device_id = <0>;
				iommus = <&mmu_aw 3 1>;
				status = "okay";
			};
			scaler1:scaler@1 {
				compatible = "allwinner,sunxi-scaler";
				reg = <0x0 0x02110400 0x0 0x400>;
				device_id = <1>;
				iommus = <&mmu_aw 3 1>;
				status = "okay";
			};
			scaler2:scaler@2 {
				compatible = "allwinner,sunxi-scaler";
				reg = <0x0 0x02110800 0x0 0x400>;
				device_id = <2>;
				iommus = <&mmu_aw 3 1>;
				status = "okay";
			};
			scaler3:scaler@3 {
				compatible = "allwinner,sunxi-scaler";
				reg = <0x0 0x02110C00 0x0 0x400>;
				device_id = <3>;
				iommus = <&mmu_aw 3 1>;
				status = "okay";
			};
			actuator0:actuator@0 {
				device_type = "actuator0";
				compatible = "allwinner,sunxi-actuator";
				actuator0_name = "ad5820_act";
				actuator0_slave = <0x18>;
				actuator0_af_pwdn = <>;
				actuator0_afvdd = "afvcc-csi";
				actuator0_afvdd_vol = <2800000>;
				status = "disabled";
			};
			flash0:flash@0 {
				device_type = "flash0";
				compatible = "allwinner,sunxi-flash";
				flash0_type = <2>;
				flash0_en = <>;
				flash0_mode = <>;
				flash0_flvdd = "";
				flash0_flvdd_vol = <>;
				device_id = <0>;
				status = "disabled";
			};
			sensor0:sensor@0 {
				device_type = "sensor0";
				compatible = "allwinner,sunxi-sensor";
				sensor0_mname = "imx278_mipi";
				sensor0_twi_cci_id = <2>;
				sensor0_twi_addr = <0x20>;
				sensor0_mclk_id = <0>;
				sensor0_pos = "rear";
				sensor0_isp_used = <1>;
				sensor0_fmt = <1>;
				sensor0_stby_mode = <0>;
				sensor0_vflip = <0>;
				sensor0_hflip = <0>;
				sensor0_iovdd-supply = <&reg_dldo2>;
				sensor0_iovdd_vol = <1800000>;
				sensor0_avdd-supply = <&reg_dldo3>;
				sensor0_avdd_vol = <2800000>;
				sensor0_dvdd-supply = <&reg_eldo2>;
				sensor0_dvdd_vol = <1200000>;
				sensor0_power_en = <>;
				sensor0_reset = <&pio PE 9 1 0 1 0>;
				sensor0_pwdn = <&pio PE 8 1 0 1 0>;
				sensor0_sm_vs = <>;
				flash_handle = <&flash0>;
				act_handle = <&actuator0>;
				device_id = <0>;
				status	= "okay";
			};
			sensor1:sensor@1 {
				device_type = "sensor1";
				compatible = "allwinner,sunxi-sensor";
				sensor1_mname = "imx386_mipi";
				sensor1_twi_cci_id = <3>;
				sensor1_twi_addr = <0x20>;
				sensor1_mclk_id = <1>;
				sensor1_pos = "front";
				sensor1_isp_used = <1>;
				sensor1_fmt = <1>;
				sensor1_stby_mode = <0>;
				sensor1_vflip = <0>;
				sensor1_hflip = <0>;
				sensor1_iovdd-supply = <&reg_dldo2>;
				sensor1_iovdd_vol = <1800000>;
				sensor1_avdd-supply = <&reg_dldo3>;
				sensor1_avdd_vol = <2800000>;
				sensor1_dvdd-supply = <&reg_eldo2>;
				sensor1_dvdd_vol = <1200000>;
				sensor1_power_en = <>;
				sensor1_reset = <&pio PE 7 1 0 1 0>;
				sensor1_pwdn = <&pio PE 6 1 0 1 0>;
				sensor1_sm_vs = <>;
				flash_handle = <>;
				act_handle = <>;
				device_id = <1>;
				sensor0_power_en = <>;
				status	= "okay";
			};
			vinc0:vinc@0 {
				device_type = "vinc0";
				compatible = "allwinner,sunxi-vin-core";
				reg = <0x0 0x02009000 0x0 0x200>;
				interrupts = <GIC_SPI 71 IRQ_TYPE_LEVEL_HIGH>;
				vinc0_csi_sel = <0>;
				vinc0_mipi_sel = <0>;
				vinc0_isp_sel = <0>;
				vinc0_tdm_rx_sel = <0>;
				vinc0_rear_sensor_sel = <0>;
				vinc0_front_sensor_sel = <1>;
				vinc0_sensor_list = <0>;
				device_id = <0>;
				iommus = <&mmu_aw 3 1>;
				vinc0_isp_tx_ch = <0>;
				status = "okay";
			};
			vinc1:vinc@1 {
				device_type = "vinc1";
				compatible = "allwinner,sunxi-vin-core";
				reg = <0x0 0x02009200 0x0 0x200>;
				interrupts = <GIC_SPI 72 IRQ_TYPE_LEVEL_HIGH>;
				vinc1_csi_sel = <0>;
				vinc1_mipi_sel = <0>;
				vinc1_isp_sel = <0>;
				vinc1_tdm_rx_sel = <0>;
				vinc1_rear_sensor_sel = <0>;
				vinc1_front_sensor_sel = <0>;
				vinc1_sensor_list = <0>;
				device_id = <1>;
				iommus = <&mmu_aw 3 1>;
				vinc1_isp_tx_ch = <0>;
				status = "okay";
			};
			vinc2:vinc@2 {
				device_type = "vinc2";
				compatible = "allwinner,sunxi-vin-core";
				reg = <0x0 0x02009400 0x0 0x200>;
				interrupts = <GIC_SPI 73 IRQ_TYPE_LEVEL_HIGH>;
				vinc2_csi_sel = <1>;
				vinc2_mipi_sel = <1>;
				vinc2_isp_sel = <1>;
				vinc2_tdm_rx_sel = <1>;
				vinc2_rear_sensor_sel = <1>;
				vinc2_front_sensor_sel = <1>;
				vinc2_sensor_list = <0>;
				device_id = <2>;
				iommus = <&mmu_aw 3 1>;
				vinc2_isp_tx_ch = <0>;
				status = "ok";
			};
			vinc3:vinc@3 {
				device_type = "vinc3";
				compatible = "allwinner,sunxi-vin-core";
				reg = <0x0 0x02009600 0x0 0x200>;
				interrupts = <GIC_SPI 74 IRQ_TYPE_LEVEL_HIGH>;
				vinc3_csi_sel = <1>;
				vinc3_mipi_sel = <1>;
				vinc3_isp_sel = <1>;
				vinc3_tdm_rx_sel = <1>;
				vinc3_rear_sensor_sel = <1>;
				vinc3_front_sensor_sel = <1>;
				vinc3_sensor_list = <0>;
				device_id = <3>;
				iommus = <&mmu_aw 3 1>;
				vinc3_isp_tx_ch = <0>;
				status = "disabled";
			};
		};

		Vdevice: vdevice@0 {
			compatible = "allwinner,sun50i-vdevice";
			device_type = "Vdevice";
			pinctrl-names = "default";
			interrupt-parent = <&pio>;
			interrupts = < PB 0 IRQ_TYPE_LEVEL_HIGH>;       /* bank offset type */
			pinctrl-0 = <&vdevice_pins_a>;
			test-gpios = <&pio PB 0 1 2 2 1>;  /* PA 0 0=in/1=out drive pull level */
			suspend-gpios = <&r_pio PL 4 1 2 2 1>;  /* PA 0 0=in/1=out drive pull level */
			wakeup-source;
			status = "disabled";
		};

		emce: emce@01905000 {
			compatible = "allwinner,sunxi-emce";
			device_name = "emce";
			reg = <0x0 0x01905000 0 0x100>;
			clock-frequency = <300000000>; /*300MHZ*/
			/*clocks = <&clk_emce>, <&clk_pll_periph0x2>;*/
		};

		cryptoengine: ce@1904000 {
			compatible = "allwinner,sunxi-ce";
			device_name = "ce";
			reg = <0x0 0x01904000 0x0 0xa0>, /* non-secure space */
			      <0x0 0x01904800 0x0 0xa0>; /* secure space */
			interrupts = <GIC_SPI 92 IRQ_TYPE_EDGE_RISING>, /* non-secure space */
				   <GIC_SPI 93 IRQ_TYPE_EDGE_RISING>; /* secure space */
			clock-frequency = <400000000>; /* 400MHz */
			clocks = <&clk_ce>, <&clk_pll_periph0x2>;
		};

		nand0:nand0@04011000 {
			compatible = "allwinner,sun50iw10-nand";
			device_type = "nand0";
			reg = <0x0 0x04011000 0x0 0x1000>;/* nand0 */
			interrupts = <GIC_SPI 38 IRQ_TYPE_LEVEL_HIGH>;
			clocks = <&clk_pll_periph0x2>,<&clk_nand0>,<&clk_nand1>;
			pinctrl-names = "default", "sleep";
			pinctrl-0 = <&nand0_pins_a &nand0_pins_b>;
			pinctrl-1 = <&nand0_pins_c>;
			nand0_regulator1 = "vcc-nand";
			nand0_regulator2 = "none";
			nand0_cache_level = <0x55aaaa55>;
			nand0_flush_cache_num = <0x55aaaa55>;
			nand0_capacity_level = <0x55aaaa55>;
			nand0_id_number_ctl = <0x55aaaa55>;
			nand0_print_level = <0x55aaaa55>;
			nand0_p0 = <0x55aaaa55>;
			nand0_p1 = <0x55aaaa55>;
			nand0_p2 = <0x55aaaa55>;
			nand0_p3 = <0x55aaaa55>;
			chip_code = "sun50iw10";
			status = "okay";
		};

		ths: thermal_sensor{
			compatible = "allwinner,sun50iw10p1-ths";
			reg = <0x0 0x05070400 0x0 0x400>;
			clocks = <&clk_ths>;
			clock-names = "bus";
			nvmem-cells = <&ths_calib>;
			nvmem-cell-names = "calibration";
			#thermal-sensor-cells = <1>;
		};

		thermal-zones {
			cpu_thermal_zone {
				polling-delay-passive = <500>;
				polling-delay = <1000>;
				thermal-sensors = <&ths 0>;
				sustainable-power = <800>;
				k_po = <24>;
				k_pu = <48>;
				k_i = <0>;

				cpu_trips: trips {
					cpu_threshold: trip-point@0 {
						temperature = <70000>;
						type = "passive";
						hysteresis = <0>;
					};
					cpu_target: trip-point@1 {
						temperature = <80000>;
						type = "passive";
						hysteresis = <0>;
					};
					cpu_crit: cpu_crit@0 {
						temperature = <110000>;
						type = "critical";
						hysteresis = <0>;
					};
				};

				cooling-maps {
					map0 {
						trip = <&cpu_target>;
						cooling-device = <&cpu0
						THERMAL_NO_LIMIT
						THERMAL_NO_LIMIT>;
						contribution = <1024>;
					};
				/*	map1{
						trip = <&cpu_target>;
						cooling-device = <&gpu
						THERMAL_NO_LIMIT
						THERMAL_NO_LIMIT>;
						contribution = <1024>;
					};	*/
				};
			};
			gpu_thermal_zone{
				polling-delay-passive = <500>;
				polling-delay = <1000>;
				thermal-sensors = <&ths 1>;
				sustainable-power = <1100>;
			};
			ddr_thermal_zone{
				polling-delay-passive = <0>;
				polling-delay = <0>;
				thermal-sensors = <&ths 2>;
			};
		};

		gpadc:gpadc{
			compatible = "allwinner,sunxi-gpadc";
			reg = <0x0 0x05070000 0x0 0x400>;
			interrupts = <GIC_SPI 20 IRQ_TYPE_NONE>;
			clocks = <&clk_gpadc>;
			channel_num = <1>;
			channel_select = <0x01>;
			channel_data_select = <0>;
			channel_compare_select = <0x01>;
			channel_cld_select = <0x01>;
			channel_chd_select = <0>;
			channel0_compare_lowdata = <1700000>;
			channel0_compare_higdata = <1200000>;
			key_cnt = <5>;
			key0_vol = <115>;
			key0_val = <115>;
			key1_vol = <240>;
			key1_val = <114>;
			key2_vol = <360>;
			key2_val = <139>;
			key3_vol = <480>;
			key3_val = <28>;
			key4_vol = <600>;
			key4_val = <102>;
			status = "okay";
		};

		keyboard0:keyboard{
			compatible = "allwinner,keyboard_1350mv";
			reg = <0x0 0x05070800 0x0 0x400>;
			interrupts = <GIC_SPI 22 IRQ_TYPE_NONE>;
			clocks = <&clk_lradc>;
			status = "okay";
			key_cnt = <5>;
			key0 = <210 115>;
			key1 = <410 114>;
			key2 = <590 139>;
			key3 = <750 28>;
			key4 = <880 102>;
		};

		gmac0: eth@05020000 {
			compatible = "allwinner,sunxi-gmac";
			reg = <0x0 0x05020000 0x0 0x10000>,
			      <0x0 0x03000030 0x0 0x4>;
			interrupts = <GIC_SPI 16 IRQ_TYPE_LEVEL_HIGH>;
			interrupt-names = "gmacirq";
			clocks = <&clk_gmac0>, <&clk_gmac0_25m>;
			clock-names = "gmac", "ephy";
			device_type = "gmac0";
			pinctrl-0 = <&gmac_pins_a>;
			pinctrl-1 = <&gmac_pins_b>;
			pinctrl-names = "default", "sleep";
			phy-mode;
			tx-delay = <7>;
			rx-delay = <31>;
			phy-rst;
			gmac-power0;
			gmac-power1;
			gmac-power2;
			status = "disable";
		};

		gmac1: eth@05030000 {
			compatible = "allwinner,sunxi-gmac";
			reg = <0x0 0x05030000 0x0 0x10000>,
			      <0x0 0x03000034 0x0 0x4>;
			interrupts = <GIC_SPI 17 IRQ_TYPE_LEVEL_HIGH>;
			interrupt-names = "gmacirq";
			clocks = <&clk_gmac1>, <&clk_gmac1_25m>;
			clock-names = "gmac", "ephy";
			device_type = "gmac1";
			pinctrl-0 = <&gmac1_pins_a>;
			pinctrl-1 = <&gmac1_pins_b>;
			pinctrl-names = "default", "sleep";
			phy-mode;
			tx-delay = <7>;
			rx-delay = <31>;
			phy-rst;
			gmac-power0;
			gmac-power1;
			gmac-power2;
			status = "disable";
		};

		standby_param: standby_param {
			vdd-cpu = <0x00000006>;
			vdd-sys = <0x00000008>;
			vcc-pll = <0x00000100>;

			osc24m-on = <0x1>;
		};

		wlan: wlan@0 {
			compatible    = "allwinner,sunxi-wlan";
			clocks        = <&clk_losc_out>;
			pinctrl-0;
			pinctrl-names;
			wlan_busnum    = <0x1>;
			wlan_power_num = <0x1>;
			wlan_power1    = "axp803-dldo1";
			wlan_io_regulator;
			wlan_regon    = <&r_pio PL 5 1 0xffffffff 0xffffffff 0>;
			wlan_hostwake = <&r_pio PL 6 6 0xffffffff 0xffffffff 0>;
			chip_en;
			power_en;
			status        = "okay";
			wakeup-source;
		};

		product {
			device_type = "product";
			version = "100";
			machine = "evb1";
		};

		platform {
			device_type = "platform";
			eraseflag = <0x11>;
			debug_mode = <0x8>;
		};

		target {
			device_type = "target";
			boot_clock = <0x3f0>;
			storage_type = <0xffffffff>;
			advert_enable = <0x0>;
			burn_key = <0x1>;
			dragonboard_test = <0x0>;
		};

		power_sply {
			device_type = "power_sply";
			dcdc1_vol = <0xf4f24>;
			aldo1_vol = <0xf4948>;
			aldo2_vol = <0xf4948>;
			aldo3_vol = <0xf4f24>;
			dldo1_vol = <0xce4>;
			eldo1_vol = <0xf4948>;
			eldo3_vol = <0xf4948>;
			fldo1_vol = <0x18a24>;
			dc1sw_vol = <0xf4f24>;
		};

		card_boot {
			device_type = "card_boot";
			logical_start = <0xa000>;
			sprite_gpio0 = <0x6e 0x7 0x6 0x1 0xffffffff 0xffffffff 0x1>;
		};

		pm_para {
			device_type = "pm_para";
			standby_mode = <0x1>;
		};

		card0_boot_para {
			device_type = "card0_boot_para";
			card_ctrl = <0x0>;
			card_high_speed = <0x1>;
			card_line = <0x4>;
			pinctrl-0 = <&card0_boot_pin>;
		};

		card2_boot_para {
			device_type = "card2_boot_para";
			card_ctrl = <0x2>;
			card_high_speed = <0x1>;
			card_line = <0x8>;
			pinctrl-0 = <&card2_boot_pin_a>,<&card2_boot_pin_b>;
			sdc_ex_dly_used = <0x2>;
		};

		gpio_bias {
			device_type = "gpio_bias";
			pc_bias = <0xce4>;
		};

		twi_para {
			device_type = "twi_para";
			twi_port = <0x0>;
			pinctrl-0 = <0x10c>;
		};

		auto_print {
			device_type = "auto_print";
			status = "disabled";
		};

		uart_para {
			device_type = "uart_para";
			uart_debug_port = <0x0>;
			pinctrl-0 = <0x10d>;
		};

		jtag_para {
			device_type = "jtag_para";
			jtag_enable = <0x0>;
			pinctrl-0 = <0x10e>;
		};

		clock {
			device_type = "clock";
			pll4 = <0x12c>;
			pll6 = <0x258>;
			pll8 = <0x168>;
			pll9 = <0x129>;
			pll10 = <0x108>;
		};

		secure {
			device_type = "secure";
			dram_region_mbytes = <0x50>;
			drm_region_mbytes = <0x0>;
			drm_region_start_mbytes = <0x0>;
		};
	};

	aliases {
		serial0 = &uart0;
		serial1 = &uart1;
		serial2 = &uart2;
		serial3 = &uart3;
		serial4 = &uart4;
		serial5 = &uart5;
		serial6 = &uart6;
		serial7 = &uart7;
		ir0 = &s_cir0;
		ir1 = &ir1;
		twi0 = &twi0;
		twi1 = &twi1;
		twi2 = &twi2;
		twi3 = &twi3;
		twi4 = &twi4;
		twi5 = &twi5;
		twi6 = &twi6;
		twi7 = &twi7;
		spi0 = &spi0;
		spi1 = &spi1;
		spi2 = &spi2;
		ledc = &ledc;
		pcie = &pcie;
		gmac0 = &gmac0;
		gmac1 = &gmac1;

		global_timer0  = &soc_timer0;
		mmc0 = &sdc0;
		mmc2 = &sdc2;
		nand0 =&nand0;
		disp = &disp;
		eink = &eink;
		tps65185 = &tps65185;
		tps65185_slave = &tps65185_slave;
		lcd0 = &lcd0;
		lcd1 = &lcd1;
		pwm = &pwm;
		pwm0 = &pwm0;
		pwm1 = &pwm1;
		pwm2 = &pwm2;
		pwm3 = &pwm3;
		pwm4 = &pwm4;
		pwm5 = &pwm5;
		pwm6 = &pwm6;
		pwm7 = &pwm7;
		pwm8 = &pwm8;
		pwm9 = &pwm9;
		pwm10 = &pwm10;
		pwm11 = &pwm11;
		pwm12 = &pwm12;
		pwm13 = &pwm13;
		pwm14 = &pwm14;
		pwm15 = &pwm15;
		ac200 = &ac200;
		boot_disp = &boot_disp;
		pmu0 = &pmu0;
		standby_param = &standby_param;
	};

	chosen {
		bootargs = "earlyprintk=sunxi-uart,0x05000000 loglevel=8 initcall_debug=0 console=ttyS0 init=/init";
		linux,initrd-start = <0x0 0x0>;
		linux,initrd-end = <0x0 0x0>;
	};

	firmware {
		android {
			compatible = "android,firmware";
			name = "android";
			boot_devices = "soc/sdc0,soc/sdc2,soc";
			vbmeta {
				compatible = "android,vbmeta";
				parts = "vbmeta,vbmeta_system,vbmeta_vendor,boot,super,recovery";
			};
		};
		optee {
			compatible = "linaro,optee-tz";
			method = "smc";
		};
	};

	cpus {
		#address-cells = <2>;
		#size-cells = <0>;

		cpu0: cpu@0 {
			device_type = "cpu";
			compatible = "arm,cortex-a53","arm,armv8";
			reg = <0x0 0x0>;
			enable-method = "psci";
			clocks = <&clk_pll_cpu>;
			clock-latency = <2000000>;
			clock-frequency = <1320000000>;
			dynamic-power-coefficient = <190>;
			operating-points-v2 = <&cpu_opp_l_table>;
			cpu-idle-states = <&CPU_SLEEP_0 &CLUSTER_SLEEP_0>;
			#cooling-cells = <2>;
			cpu-supply = <&reg_dcdc2>;
		};

		cpu@1 {
			device_type = "cpu";
			compatible = "arm,cortex-a53","arm,armv8";
			reg = <0x0 0x1>;
			enable-method = "psci";
			clocks = <&clk_pll_cpu>;
			clock-frequency = <1320000000>;
			operating-points-v2 = <&cpu_opp_l_table>;
			cpu-idle-states = <&CPU_SLEEP_0 &CLUSTER_SLEEP_0>;
			#cooling-cells = <2>;
		};

		cpu@2 {
			device_type = "cpu";
			compatible = "arm,cortex-a53","arm,armv8";
			reg = <0x0 0x2>;
			enable-method = "psci";
			clocks = <&clk_pll_cpu>;
			clock-frequency = <1320000000>;
			operating-points-v2 = <&cpu_opp_l_table>;
			cpu-idle-states = <&CPU_SLEEP_0 &CLUSTER_SLEEP_0>;
			#cooling-cells = <2>;
		};

		cpu@3 {
			device_type = "cpu";
			compatible = "arm,cortex-a53","arm,armv8";
			reg = <0x0 0x3>;
			enable-method = "psci";
			clocks = <&clk_pll_cpu>;
			clock-frequency = <1320000000>;
			operating-points-v2 = <&cpu_opp_l_table>;
			cpu-idle-states = <&CPU_SLEEP_0 &CLUSTER_SLEEP_0>;
			#cooling-cells = <2>;
		};

		idle-states {
			entry-method = "arm,psci";

			CPU_SLEEP_0: cpu-sleep-0 {
				compatible = "arm,idle-state";
				arm,psci-suspend-param = <0x0010000>;
				entry-latency-us = <46>;
				exit-latency-us = <59>;
				min-residency-us = <3570>;
				local-timer-stop;
			};

			CLUSTER_SLEEP_0: cluster-sleep-0 {
				compatible = "arm,idle-state";
				arm,psci-suspend-param = <0x1010000>;
				entry-latency-us = <47>;
				exit-latency-us = <74>;
				min-residency-us = <5000>;
				local-timer-stop;
			};
		};
	};

	cpu_opp_l_table: opp_l_table {
		compatible = "operating-points-v2";
		opp-shared;

		opp@408000000 {
			opp-hz = /bits/ 64 <408000000>;
			opp-microvolt = <840000>;
			clock-latency-ns = <244144>; /* 8 32k periods */
		};
		opp@600000000 {
			opp-hz = /bits/ 64 <600000000>;
			opp-microvolt = <840000>;
			clock-latency-ns = <244144>; /* 8 32k periods */
		};
		opp@816000000 {
			opp-hz = /bits/ 64 <816000000>;
			opp-microvolt = <880000>;
			clock-latency-ns = <244144>; /* 8 32k periods */
		};
		opp@1008000000 {
			opp-hz = /bits/ 64 <1008000000>;
			opp-microvolt = <940000>;
			clock-latency-ns = <244144>; /* 8 32k periods */
		};
		opp@1200000000 {
			opp-hz = /bits/ 64 <1200000000>;
			opp-microvolt = <1020000>;
			clock-latency-ns = <244144>; /* 8 32k periods */
		};
		opp@1416000000 {
			opp-hz = /bits/ 64 <1416000000>;
			opp-microvolt = <1100000>;
			clock-latency-ns = <244144>; /* 8 32k periods */
		};
		opp@1512000000 {
			opp-hz = /bits/ 64 <1512000000>;
			opp-microvolt = <1180000>;
			clock-latency-ns = <244144>; /* 8 32k periods */
		};
	};

	psci {
	    compatible		=  "arm,psci-1.0";
	    method		=  "smc";
	};

	n_brom {
		compatible = "allwinner,n-brom";
		reg = <0x0 0x0 0x0 0xa000>;
	};

	s_brom {
		compatible = "allwinner,s-brom";
		reg = <0x0 0x0 0x0 0x10000>;
	};

	sram_ctrl {
		device_type = "sram_ctrl";
		compatible = "allwinner,sram_ctrl";
		reg = <0x0 0x03000000 0x0 0x100>;
	};

	sram_a1 {
		compatible = "allwinner,sram_a1";
		reg = <0x0 0x00020000 0x0 0x8000>;
	};

	sram_a2 {
		compatible = "allwinner,sram_a2";
		reg = <0x0 0x00100000 0x0 0x14000>;
	};

	prcm {
		compatible = "allwinner,prcm";
		reg = <0x0 0x01f01400 0x0 0x400>;
	};

	s_cpuscfg {
		compatible = "allwinner,s_cpuscfg";
		reg = <0x0 0x01f01c00 0x0 0x400>;
	};

	ion {
		compatible = "allwinner,sunxi-ion";
		/*types is list here:
			ION_HEAP_TYPE_SYSTEM = 0,
			ION_HEAP_TYPE_SYSTEM_CONTIG = 1,
			ION_HEAP_TYPE_CARVEOUT = 2,
			ION_HEAP_TYPE_CHUNK = 3,
			ION_HEAP_TYPE_DMA = 4,
			ION_HEAP_TYPE_SECURE = 6,
		**/
		heap_sys_user@0{
			compatible = "allwinner,sys_user";
			heap-name  = "sys_user";
			heap-id    = <0x0>;
			heap-base  = <0x0>;
			heap-size  = <0x0>;
			heap-type  = "ion_system";
		};
		heap_cma@0{
			compatible = "allwinner,cma";
			heap-name  = "cma";
			heap-id    = <0x4>;
			heap-base  = <0x0>;
			heap-size  = <0x0>;
			heap-type  = "ion_cma";
		};
		heap_secure@0{
			compatible = "allwinner,secure";
			heap-name  = "secure";
			heap-id    = <0x6>;
			heap-base  = <0x0>;
			heap-size  = <0x0>;
			heap-type  = "ion_secure";
		};
	};

	dram: dram {
		compatible = "allwinner,dram";
		clocks = <&clk_pll_ddr>;
		clock-names = "pll_ddr";
		dram_clk        = <672>;
		dram_type       = <3>;
		dram_zq         = <0x003F3FDD>;
		dram_odt_en     = <1>;
		dram_para1      = <0x10f41000>;
		dram_para2      = <0x00001200>;
		dram_mr0        = <0x1A50>;
		dram_mr1        = <0x40>;
		dram_mr2        = <0x10>;
		dram_mr3        = <0>;
		dram_tpr0       = <0x04E214EA>;
		dram_tpr1       = <0x004214AD>;
		dram_tpr2       = <0x10A75030>;
		dram_tpr3       = <0>;
		dram_tpr4       = <0>;
		dram_tpr5       = <0>;
		dram_tpr6       = <0>;
		dram_tpr7       = <0>;
		dram_tpr8       = <0>;
		dram_tpr9       = <0>;
		dram_tpr10      = <0>;
		dram_tpr11      = <0>;
		dram_tpr12      = <168>;
		dram_tpr13      = <0x823>;
		device_type = "dram";
		dram_dx_odt = <0x7070707>;
		dram_dx_dri = <0xc0c0c0c>;
		dram_ca_dri = <0xe0e>;
		dram_para0 = <0x15101212>;
		dram_mr4 = <0x0>;
		dram_mr5 = <0x0>;
		dram_mr6 = <0x0>;
		dram_mr11 = <0x0>;
		dram_mr12 = <0x0>;
		dram_mr13 = <0x0>;
		dram_mr14 = <0x0>;
		dram_mr16 = <0x0>;
		dram_mr17 = <0x0>;
		dram_mr22 = <0x0>;
		dram_tpr14 = <0x26232323>;
	};

	memory@40000000 {
		device_type = "memory";
		reg = <0x00000000 0x40000000 0x00000000 0x20000000>;
	};

	gic: interrupt-controller@03020000 {
		compatible = "arm,cortex-a15-gic", "arm,cortex-a9-gic";
		#interrupt-cells = <3>;
		#address-cells = <0>;
		device_type = "gic";
		interrupt-controller;
		reg = <0x0 0x03021000 0 0x1000>, /* GIC Dist */
		      <0x0 0x03022000 0 0x2000>, /* GIC CPU */
		      <0x0 0x03024000 0 0x2000>, /* GIC VCPU Control */
		      <0x0 0x03026000 0 0x2000>; /* GIC VCPU */
		interrupts = <GIC_PPI 9 0xf04>; /* GIC Maintenence IRQ */
		interrupt-parent = <&gic>;
	};

	wakeupgen: interrupt-controller@0 {
		compatible = "allwinner,sunxi-wakeupgen";
		interrupt-controller;
		#interrupt-cells = <3>;
		interrupt-parent = <&gic>;
	};

	nmi_intc: intc-nmi@07010320 {
		compatible = "allwinner,sun8i-nmi";
		interrupt-parent = <&gic>;
		#interrupt-cells = <2>;
		#address-cells = <0>;
		interrupt-controller;
		reg = <0x0 0x07010320 0 0xc>;
		interrupts = <GIC_SPI 103 IRQ_TYPE_LEVEL_HIGH>;
	};

	sid: sunxi-sid@03006000 {
		compatible = "allwinner,sunxi-sid";
		device_type = "sid";
		reg = <0x0 0x03006000 0 0x1000>;
	};

	sunxi-sid-ng@03006000 {
		compatible = "allwinner,sun50iw10p1-sid";
		reg = <0x0 0x03006000 0 0x1000>;
		#address-cells = <1>;
		#size-cells = <1>;

		ths_calib: calib@14 {
			reg = <0x14 8>;
		};
	};

	chipid: sunxi-chipid@03006200 {
		compatible = "allwinner,sunxi-chipid";
		device_type = "chipid";
		reg = <0x0 0x03006200 0 0x0200>;
	};

	timer_arch {
		compatible = "arm,armv8-timer";
		interrupts = <GIC_PPI 13 (GIC_CPU_MASK_SIMPLE(4) | IRQ_TYPE_LEVEL_LOW)>,
			   <GIC_PPI 14 (GIC_CPU_MASK_SIMPLE(4) | IRQ_TYPE_LEVEL_LOW)>,
			   <GIC_PPI 11 (GIC_CPU_MASK_SIMPLE(4) | IRQ_TYPE_LEVEL_LOW)>,
			   <GIC_PPI 10 (GIC_CPU_MASK_SIMPLE(4) | IRQ_TYPE_LEVEL_LOW)>;
		clock-frequency = <24000000>;
		interrupt-parent = <&gic>;
		arm,no-tick-in-suspend;
	};

	pd_gpu: gpu-power-domain@07001000 {
		   compatible = "allwinner,gpu-pd", "syscon";
		   reg = <0x0 0x07001000 0x0 0x40>;
		   interrupts = <GIC_SPI 119 IRQ_TYPE_LEVEL_HIGH>;
		   interrupt-names = "ppu-irq";
		   clocks = <&clk_ppu>;
		   clock-names = "ppu";
		   #power-domain-cells = <0>;
	};

	pmu {
		compatible = "arm,armv8-pmuv3";
		interrupts = <GIC_SPI 140 IRQ_TYPE_LEVEL_HIGH>,
			     <GIC_SPI 141 IRQ_TYPE_LEVEL_HIGH>,
			     <GIC_SPI 142 IRQ_TYPE_LEVEL_HIGH>,
			     <GIC_SPI 143 IRQ_TYPE_LEVEL_HIGH>;
	};

	dramfreq {
		compatible = "allwinner,sunxi-dramfreq";
		reg = <0x0 0x04002000 0x0 0x1000>,
		      <0x0 0x04003000 0x0 0x3000>,
		      <0x0 0x03001000 0x0 0x1000>;
		interrupts = <GIC_SPI 33 IRQ_TYPE_LEVEL_HIGH>;
		clocks = <&clk_pll_ddr>;
		status = "okay";
	};

	uboot: uboot {
	};

	mmu_aw: iommu@030f0000 {
		compatible = "allwinner,sunxi-iommu";
		reg = <0x0 0x030f0000 0x0 0x1000>;
		interrupts = <GIC_SPI 66 IRQ_TYPE_LEVEL_HIGH>;
		interrupt-names = "iommu-irq";
		clocks = <&clk_iommu>;
		clock-names = "iommu";
		/* clock-frequency = <24000000>; */
		#iommu-cells = <2>;
		status = "okay";
	};

	reg_usb1_vbus: usb1-vbus {
		compatible = "regulator-fixed";
		gpio = <&pio PF 4 1 2 0 1>;
		regulator-name = "usb1-vbus";
		regulator-min-microvolt = <5000000>;
		regulator-max-microvolt = <5000000>;
		enable-active-high;
	};

	gpu: gpu@0x01800000 {
		device_type = "gpu";
		compatible = "img,gpu";
		reg = <0x0 0x01800000 0x0 0x80000>;
		interrupts = <GIC_SPI 97 IRQ_TYPE_LEVEL_HIGH>;
		interrupt-names = "IRQGPU";
		clocks = <&clk_pll_gpu>, <&clk_gpu>;
		clock-names = "clk_parent", "clk_mali";
		power-domains = <&pd_gpu>;
			gpu_idle = <0>;
			dvfs_status = <0>;
			pll_rate = <564000>;
			operating-points = <
				 /* KHz   uV */
				458250 950000
				282000 950000
				264375 950000
				246750 950000
				229125 950000
			 >;
	};
};
